VERSION "GM Global B Super Cruise 1 CAN2"
NS_ :

BS_:
BU_: ACP3_MCU CGM ECP_E EBCM EPS ARS BCM DSM TCP VICM RRR_SIDE Vector__XXX

BO_ 47 ECP_E_AXLE_TORQUE: 32 ECP_E
 SG_ AUTHENTICATOR : 7|32@0+ (1,0) [0|4294967295] "" Vector__XXX
 SG_ SECOC_FRESHNESS : 39|5@0+ (1,0) [0|31] "" Vector__XXX
 SG_ SECOC_AUX : 34|3@0+ (1,0) [0|7] "" Vector__XXX
 SG_ ActualAxleTorque : 47|15@0+ (2,-22534) [-22534|43000] "Nm" Vector__XXX
 SG_ ActualAxleTorqueInvalid : 48|1@0+ (1,0) [0|1] "" Vector__XXX
 SG_ SecondaryAxleTorque : 176|15@0+ (2,-22534) [-22534|43000] "Nm" Vector__XXX
 SG_ SecondaryAxleTorqueInvalid : 193|1@0+ (1,0) [0|1] "" Vector__XXX
 SG_ RollingCounter : 239|2@0+ (1,0) [0|3] "" Vector__XXX

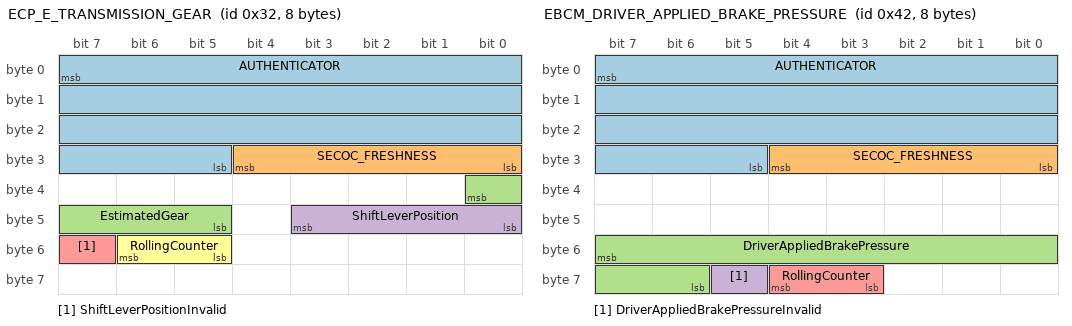
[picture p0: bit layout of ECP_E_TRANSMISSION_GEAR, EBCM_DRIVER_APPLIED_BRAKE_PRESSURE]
BO_ 50 ECP_E_TRANSMISSION_GEAR: 8 ECP_E
 SG_ AUTHENTICATOR : 7|27@0+ (1,0) [0|134217727] "" Vector__XXX
 SG_ SECOC_FRESHNESS : 28|5@0+ (1,0) [0|31] "" Vector__XXX
 SG_ EstimatedGear : 32|4@0+ (1,0) [0|15] "" Vector__XXX
 SG_ ShiftLeverPosition : 43|4@0+ (1,0) [0|15] "" Vector__XXX
 SG_ ShiftLeverPositionInvalid : 55|1@0+ (1,0) [0|1] "" Vector__XXX
 SG_ RollingCounter : 54|2@0+ (1,0) [0|3] "" Vector__XXX

BO_ 58 CAN2_RX_03A: 20 EPS
 SG_ AUTHENTICATOR : 7|32@0+ (1,0) [0|4294967295] "" Vector__XXX
 SG_ SECOC_FRESHNESS : 39|5@0+ (1,0) [0|31] "" Vector__XXX
 SG_ SECOC_AUX : 34|3@0+ (1,0) [0|7] "" Vector__XXX
 SG_ RollingCounter : 135|2@0+ (1,0) [0|3] "" Vector__XXX

BO_ 59 EBCM_BRAKE_WHEEL_DATA: 64 EBCM
 SG_ AUTHENTICATOR : 7|32@0+ (1,0) [0|4294967295] "" Vector__XXX
 SG_ SECOC_FRESHNESS : 39|5@0+ (1,0) [0|31] "" Vector__XXX
 SG_ SECOC_AUX : 34|3@0+ (1,0) [0|7] "" Vector__XXX
 SG_ BrakePedalPosition : 105|8@0+ (0.392157,0) [0|100] "%" Vector__XXX
 SG_ BrakePedalPositionInvalid : 113|1@0+ (1,0) [0|1] "" Vector__XXX
 SG_ ChassisBrakeAxleTorque : 209|14@0+ (2,0) [0|32766] "Nm" Vector__XXX
 SG_ ChassisBrakeAxleTorqueInvalid : 227|1@0+ (1,0) [0|1] "" Vector__XXX
 SG_ DriverIntendedTotalBrakeTorque : 226|14@0+ (2,0) [0|32766] "Nm" Vector__XXX
 SG_ LeftFrontWheelDistanceEdges : 244|11@0+ (1,0) [0|2047] "edges" Vector__XXX
 SG_ LeftFrontWheelDistanceInvalid : 249|1@0+ (1,0) [0|1] "" Vector__XXX
 SG_ RightFrontWheelDistanceEdges : 248|11@0+ (1,0) [0|2047] "edges" Vector__XXX
 SG_ RightFrontWheelDistanceInvalid : 269|1@0+ (1,0) [0|1] "" Vector__XXX
 SG_ FrontWheelDistanceResetOccurrence : 268|1@0+ (1,0) [0|1] "" Vector__XXX
 SG_ LeftRearWheelDistanceEdges : 303|11@0+ (1,0) [0|2047] "edges" Vector__XXX
 SG_ LeftRearWheelDistanceInvalid : 308|1@0+ (1,0) [0|1] "" Vector__XXX
 SG_ RightRearWheelDistanceEdges : 307|11@0+ (1,0) [0|2047] "edges" Vector__XXX
 SG_ RightRearWheelDistanceInvalid : 312|1@0+ (1,0) [0|1] "" Vector__XXX
 SG_ RearWheelDistanceResetOccurrence : 327|1@0+ (1,0) [0|1] "" Vector__XXX
 SG_ LeftFrontWheelAngularVelocity : 356|14@0- (0.004,0) [-32.768|32.764] "rad/s" Vector__XXX
 SG_ LeftFrontWheelAngularVelocityInvalid : 374|1@0+ (1,0) [0|1] "" Vector__XXX
 SG_ RightFrontWheelAngularVelocity : 373|14@0- (0.004,0) [-32.768|32.764] "rad/s" Vector__XXX
 SG_ RightFrontWheelAngularVelocityInvalid : 391|1@0+ (1,0) [0|1] "" Vector__XXX
 SG_ LeftRearWheelAngularVelocity : 390|14@0- (0.004,0) [-32.768|32.764] "rad/s" Vector__XXX
 SG_ LeftRearWheelAngularVelocityInvalid : 392|1@0+ (1,0) [0|1] "" Vector__XXX
 SG_ RightRearWheelAngularVelocity : 407|14@0- (0.004,0) [-32.768|32.764] "rad/s" Vector__XXX
 SG_ RightRearWheelAngularVelocityInvalid : 409|1@0+ (1,0) [0|1] "" Vector__XXX
 SG_ RollingCounter : 455|2@0+ (1,0) [0|3] "" Vector__XXX

BO_ 62 CAN2_RX_03E: 8 BCM

BO_ 63 ECP_E_NOMINAL_ROAD_LOAD_AXLE_TORQUE: 4 ECP_E
 SG_ NominalRoadLoadAxleTorque : 7|19@0- (0.125,-22534) [-55302|10233.875] "Nm" Vector__XXX

BO_ 66 EBCM_DRIVER_APPLIED_BRAKE_PRESSURE: 8 EBCM
 SG_ AUTHENTICATOR : 7|27@0+ (1,0) [0|134217727] "" Vector__XXX
 SG_ SECOC_FRESHNESS : 28|5@0+ (1,0) [0|31] "" Vector__XXX
 SG_ DriverAppliedBrakePressure : 55|10@0+ (20,0) [0|20460] "" Vector__XXX
 SG_ DriverAppliedBrakePressureInvalid : 61|1@0+ (1,0) [0|1] "" Vector__XXX
 SG_ RollingCounter : 60|2@0+ (1,0) [0|3] "" Vector__XXX

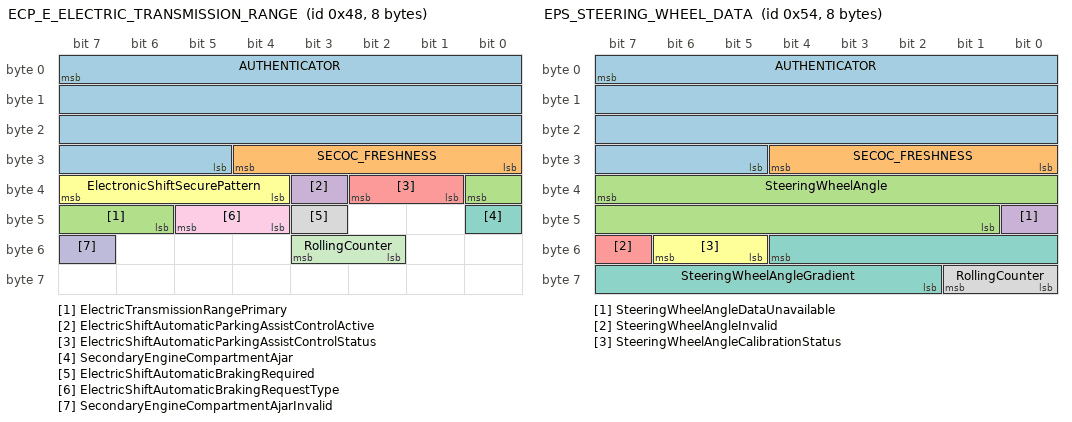
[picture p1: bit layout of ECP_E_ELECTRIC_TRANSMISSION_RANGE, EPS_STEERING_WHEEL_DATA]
BO_ 72 ECP_E_ELECTRIC_TRANSMISSION_RANGE: 8 ECP_E
 SG_ AUTHENTICATOR : 7|27@0+ (1,0) [0|134217727] "" Vector__XXX
 SG_ SECOC_FRESHNESS : 28|5@0+ (1,0) [0|31] "" Vector__XXX
 SG_ ElectricTransmissionRangePrimary : 32|3@0+ (1,0) [0|7] "" Vector__XXX
 SG_ ElectricShiftAutomaticParkingAssistControlActive : 35|1@0+ (1,0) [0|1] "" Vector__XXX
 SG_ ElectricShiftAutomaticParkingAssistControlStatus : 34|2@0+ (1,0) [0|3] "" Vector__XXX
 SG_ ElectronicShiftSecurePattern : 39|4@0+ (1,0) [0|15] "" Vector__XXX
 SG_ SecondaryEngineCompartmentAjar : 40|1@0+ (1,0) [0|1] "" Vector__XXX
 SG_ ElectricShiftAutomaticBrakingRequired : 43|1@0+ (1,0) [0|1] "" Vector__XXX
 SG_ ElectricShiftAutomaticBrakingRequestType : 45|2@0+ (1,0) [0|3] "" Vector__XXX
 SG_ SecondaryEngineCompartmentAjarInvalid : 55|1@0+ (1,0) [0|1] "" Vector__XXX
 SG_ RollingCounter : 51|2@0+ (1,0) [0|3] "" Vector__XXX

BO_ 84 EPS_STEERING_WHEEL_DATA: 8 EPS
 SG_ AUTHENTICATOR : 7|27@0+ (1,0) [0|134217727] "" Vector__XXX
 SG_ SECOC_FRESHNESS : 28|5@0+ (1,0) [0|31] "" Vector__XXX
 SG_ SteeringWheelAngle : 39|15@0- (0.0625,0) [-1024|1023.9375] "deg" Vector__XXX
 SG_ SteeringWheelAngleDataUnavailable : 40|1@0+ (1,0) [0|1] "" Vector__XXX
 SG_ SteeringWheelAngleInvalid : 55|1@0+ (1,0) [0|1] "" Vector__XXX
 SG_ SteeringWheelAngleCalibrationStatus : 54|2@0+ (1,0) [0|3] "" Vector__XXX
 SG_ SteeringWheelAngleGradient : 52|11@0- (2,0) [-2048|2046] "deg/s" Vector__XXX
 SG_ RollingCounter : 57|2@0+ (1,0) [0|3] "" Vector__XXX

BO_ 87 ACP3_MCU_HOST_VEHICLE_DYNAMICS: 32 ACP3_MCU
 SG_ AUTHENTICATOR : 7|32@0+ (1,0) [0|4294967295] "" Vector__XXX
 SG_ SECOC_FRESHNESS : 39|5@0+ (1,0) [0|31] "" Vector__XXX
 SG_ SECOC_AUX : 34|3@0+ (1,0) [0|7] "" Vector__XXX
 SG_ VehicleLateralVelocity : 46|8@0+ (0.05,-6.4) [-6.4|6.35] "m/s" Vector__XXX
 SG_ DynField02 : 47|1@0+ (1,0) [0|1] "" Vector__XXX
 SG_ VehicleLongitudinalVelocity : 53|12@0+ (0.0625,-128) [-128|127.9375] "m/s" Vector__XXX
 SG_ DynField04 : 54|1@0+ (1,0) [0|1] "" Vector__XXX
 SG_ DynField05 : 56|16@0- (0.00001,0) [-0.32768|0.32767] "1/m" Vector__XXX
 SG_ DynField06 : 57|1@0+ (1,0) [0|1] "" Vector__XXX
 SG_ DynField07 : 72|15@0+ (0.001,-16) [-16|16.767] "1/(m*s)" Vector__XXX
 SG_ DynField08 : 89|2@0+ (1,0) [0|3] "" Vector__XXX
 SG_ VehicleSideslipAngle : 103|12@0+ (0.0625,-128) [-128|127.9375] "deg" Vector__XXX
 SG_ DynField10 : 107|14@0+ (1,-8192) [-8192|8191] "m" Vector__XXX
 SG_ DynField11 : 125|8@0+ (0.1,-12.8) [-12.8|12.7] "m" Vector__XXX
 SG_ DynField12 : 131|12@0+ (0.0625,-128) [-128|127.9375] "m/s" Vector__XXX
 SG_ DynField13 : 133|2@0+ (1,0) [0|3] "" Vector__XXX
 SG_ VehicleYawRate : 150|12@0+ (0.0625,-128) [-128|127.9375] "deg/s" Vector__XXX
 SG_ DynField15 : 151|1@0+ (1,0) [0|1] "" Vector__XXX
 SG_ DynField16 : 153|2@0+ (1,0) [0|3] "" Vector__XXX
 SG_ DynField17 : 154|1@0+ (1,0) [0|1] "" Vector__XXX
 SG_ SourceTime : 167|32@0+ (1,0) [0|4294967295] "ms" Vector__XXX
 SG_ RollingCounter : 193|2@0+ (1,0) [0|3] "" Vector__XXX
 SG_ DynField20 : 195|2@0+ (1,0) [0|3] "" Vector__XXX
 SG_ DynField21 : 199|2@0+ (1,0) [0|3] "" Vector__XXX
 SG_ DynField22 : 201|9@0- (1,0) [-256|255] "mm" Vector__XXX
 SG_ DynField23 : 203|2@0+ (1,0) [0|3] "" Vector__XXX
 SG_ DynField24 : 207|4@0+ (1,0) [0|15] "" Vector__XXX
 SG_ DynField25 : 208|1@0+ (1,0) [0|1] "" Vector__XXX
 SG_ DynField26 : 223|1@0+ (1,0) [0|1] "" Vector__XXX
 SG_ FrontRoadWheelAngle : 222|10@0- (0.00436332313,0) [-2.23402144256|2.22965811943] "rad" Vector__XXX
 SG_ FrontRoadWheelAngleStatus : 228|1@0+ (1,0) [0|1] "" Vector__XXX
 SG_ DynField27 : 227|2@0+ (1,0) [0|3] "" Vector__XXX

BO_ 174 CAN2_RX_0AE: 6 ECP_E

BO_ 175 CAN2_RX_0AF: 6 ECP_E

BO_ 182 CAN2_RX_0B6: 4 CGM

BO_ 186 CAN2_RX_0BA: 12 CGM

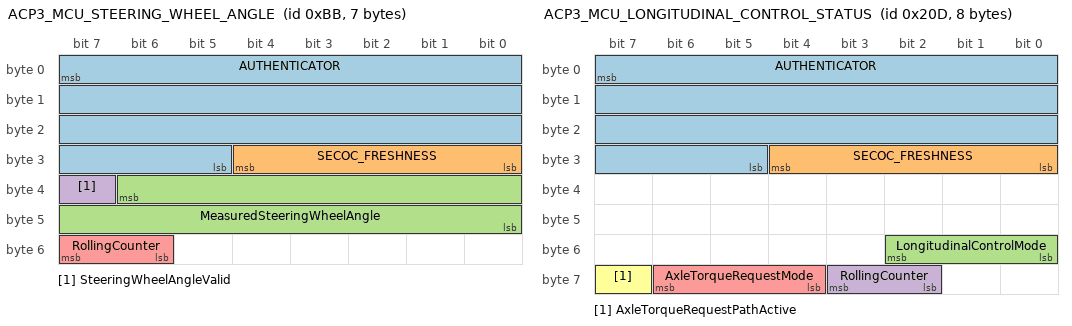
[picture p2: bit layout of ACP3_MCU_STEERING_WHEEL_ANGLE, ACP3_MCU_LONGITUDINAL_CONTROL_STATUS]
BO_ 187 ACP3_MCU_STEERING_WHEEL_ANGLE: 7 ACP3_MCU
 SG_ AUTHENTICATOR : 7|27@0+ (1,0) [0|134217727] "" Vector__XXX
 SG_ SECOC_FRESHNESS : 28|5@0+ (1,0) [0|31] "" Vector__XXX
 SG_ MeasuredSteeringWheelAngle : 38|15@0- (0.0625,0) [-1024|1023.9375] "deg" Vector__XXX
 SG_ SteeringWheelAngleValid : 39|1@0+ (1,0) [0|1] "" Vector__XXX
 SG_ RollingCounter : 55|2@0+ (1,0) [0|3] "" Vector__XXX

BO_ 192 CAN2_RX_0C0: 2 EBCM

BO_ 225 ACP3_MCU_0E1: 16 ACP3_MCU

BO_ 226 CAN2_RX_0E2: 20 ECP_E
 SG_ AUTHENTICATOR : 7|32@0+ (1,0) [0|4294967295] "" Vector__XXX
 SG_ SECOC_FRESHNESS : 39|5@0+ (1,0) [0|31] "" Vector__XXX
 SG_ SECOC_AUX : 34|3@0+ (1,0) [0|7] "" Vector__XXX

BO_ 525 ACP3_MCU_LONGITUDINAL_CONTROL_STATUS: 8 ACP3_MCU
 SG_ AUTHENTICATOR : 7|27@0+ (1,0) [0|134217727] "" Vector__XXX
 SG_ SECOC_FRESHNESS : 28|5@0+ (1,0) [0|31] "" Vector__XXX
 SG_ LongitudinalControlMode : 48|3@1+ (1,0) [0|7] "" Vector__XXX
 SG_ RollingCounter : 58|2@1+ (1,0) [0|3] "" Vector__XXX
 SG_ AxleTorqueRequestMode : 60|3@1+ (1,0) [0|7] "" Vector__XXX
 SG_ AxleTorqueRequestPathActive : 63|1@1+ (1,0) [0|1] "" Vector__XXX

BO_ 526 ACP3_MCU_LONGITUDINAL_REQUEST_STATUS: 16 ACP3_MCU
 SG_ AUTHENTICATOR : 7|32@0+ (1,0) [0|4294967295] "" Vector__XXX
 SG_ SECOC_FRESHNESS : 39|5@0+ (1,0) [0|31] "" Vector__XXX
 SG_ SECOC_AUX : 34|3@0+ (1,0) [0|7] "" Vector__XXX
 SG_ AxleTorqueRequestActive : 47|1@0+ (1,0) [0|1] "" Vector__XXX
 SG_ AdaptiveCruiseBrakeControlActive : 71|1@0+ (1,0) [0|1] "" Vector__XXX
 SG_ AdaptiveCruiseBrakeRequestActive : 70|1@0+ (1,0) [0|1] "" Vector__XXX
 SG_ CollisionMitigationBrakeTorqueRequestActive : 86|1@0+ (1,0) [0|1] "" Vector__XXX
 SG_ LaneCenteringAcceleratorLimitRequest : 101|1@0+ (1,0) [0|1] "" Vector__XXX

BO_ 545 CAN2_RX_221: 48 Vector__XXX

BO_ 586 CAN2_RX_24A: 8 Vector__XXX

BO_ 587 ACP3_MCU_AXLE_TORQUE_STATUS: 12 ACP3_MCU
 SG_ AUTHENTICATOR : 7|32@0+ (1,0) [0|4294967295] "" Vector__XXX
 SG_ SECOC_FRESHNESS : 39|5@0+ (1,0) [0|31] "" Vector__XXX
 SG_ SECOC_AUX : 34|3@0+ (1,0) [0|7] "" Vector__XXX
 SG_ AxleTorqueFieldA : 47|15@0+ (2.0,-22534) [-22534|43000] "" Vector__XXX
 SG_ AxleTorqueFieldB : 48|14@0+ (2.0,-22534) [-22534|10232] "" Vector__XXX
 SG_ AxleTorqueStatusA : 66|2@0+ (1,0) [0|3] "" Vector__XXX
 SG_ AxleTorqueStatusB : 64|2@0+ (1,0) [0|3] "" Vector__XXX
 SG_ AxleTorqueValid : 78|1@0+ (1,0) [0|1] "" Vector__XXX
 SG_ RollingCounter : 89|2@0+ (1,0) [0|3] "" Vector__XXX

BO_ 597 CAN2_RX_255: 8 CGM

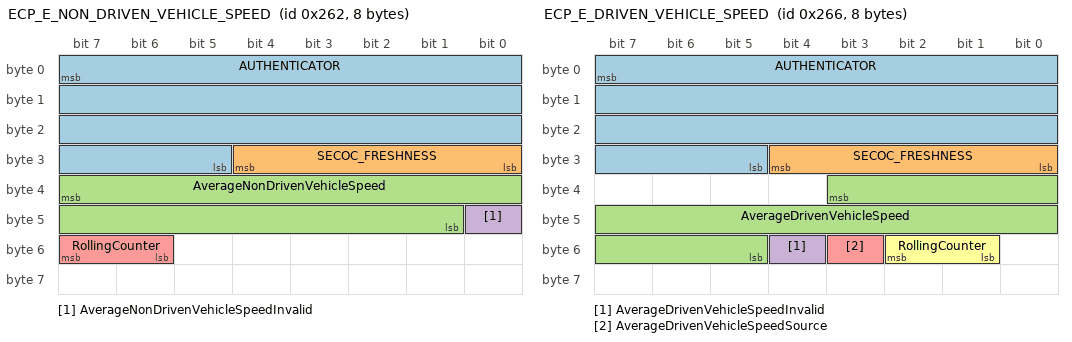
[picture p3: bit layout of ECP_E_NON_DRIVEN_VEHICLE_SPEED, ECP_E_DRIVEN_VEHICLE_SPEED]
BO_ 610 ECP_E_NON_DRIVEN_VEHICLE_SPEED: 8 ECP_E
 SG_ AUTHENTICATOR : 7|27@0+ (1,0) [0|134217727] "" Vector__XXX
 SG_ SECOC_FRESHNESS : 28|5@0+ (1,0) [0|31] "" Vector__XXX
 SG_ AverageNonDrivenVehicleSpeed : 39|15@0+ (0.015625,0) [0|511.984375] "m/s" Vector__XXX
 SG_ AverageNonDrivenVehicleSpeedInvalid : 40|1@0+ (1,0) [0|1] "" Vector__XXX
 SG_ RollingCounter : 55|2@0+ (1,0) [0|3] "" Vector__XXX

BO_ 614 ECP_E_DRIVEN_VEHICLE_SPEED: 8 ECP_E
 SG_ AUTHENTICATOR : 7|27@0+ (1,0) [0|134217727] "" Vector__XXX
 SG_ SECOC_FRESHNESS : 28|5@0+ (1,0) [0|31] "" Vector__XXX
 SG_ AverageDrivenVehicleSpeed : 35|15@0+ (0.015625,0) [0|511.984375] "m/s" Vector__XXX
 SG_ AverageDrivenVehicleSpeedInvalid : 52|1@0+ (1,0) [0|1] "" Vector__XXX
 SG_ AverageDrivenVehicleSpeedSource : 51|1@0+ (1,0) [0|1] "" Vector__XXX
 SG_ RollingCounter : 50|2@0+ (1,0) [0|3] "" Vector__XXX

BO_ 615 CAN2_RX_267: 20 ECP_E
 SG_ AUTHENTICATOR : 7|32@0+ (1,0) [0|4294967295] "" Vector__XXX
 SG_ SECOC_FRESHNESS : 39|5@0+ (1,0) [0|31] "" Vector__XXX
 SG_ SECOC_AUX : 34|3@0+ (1,0) [0|7] "" Vector__XXX

BO_ 616 CAN2_RX_268: 8 VICM

BO_ 622 CAN2_RX_26E: 8 CGM

BO_ 624 EBCM_WHEEL_ROTATION_DIRECTIONAL_STATUS: 12 EBCM
 SG_ AUTHENTICATOR : 7|32@0+ (1,0) [0|4294967295] "" Vector__XXX
 SG_ SECOC_FRESHNESS : 39|5@0+ (1,0) [0|31] "" Vector__XXX
 SG_ SECOC_AUX : 34|3@0+ (1,0) [0|7] "" Vector__XXX
 SG_ ActualVehicleAcceleration : 43|12@0- (0.01,0) [-20.48|20.47] "m/s^2" Vector__XXX
 SG_ ActualVehicleAccelerationInvalid : 63|1@0+ (1,0) [0|1] "" Vector__XXX
 SG_ LeftFrontWheelDirection : 62|3@0+ (1,0) [0|7] "" Vector__XXX
 SG_ LeftRearWheelDirection : 59|3@0+ (1,0) [0|7] "" Vector__XXX
 SG_ RightFrontWheelDirection : 56|3@0+ (1,0) [0|7] "" Vector__XXX
 SG_ RightRearWheelDirection : 69|3@0+ (1,0) [0|7] "" Vector__XXX
 SG_ RollingCounter : 66|2@0+ (1,0) [0|3] "" Vector__XXX

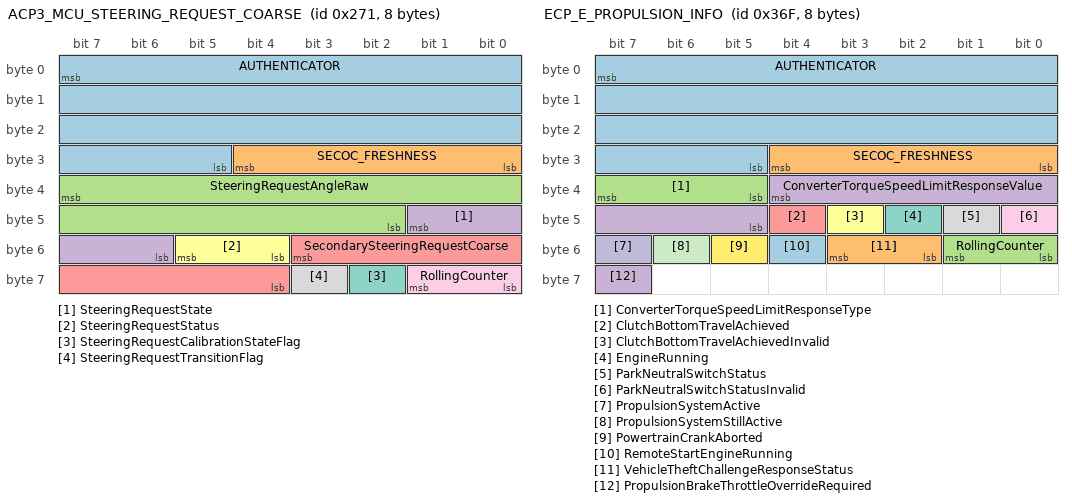
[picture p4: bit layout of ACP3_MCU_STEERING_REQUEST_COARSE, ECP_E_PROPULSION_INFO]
BO_ 625 ACP3_MCU_STEERING_REQUEST_COARSE: 8 ACP3_MCU
 SG_ AUTHENTICATOR : 7|27@0+ (1,0) [0|134217727] "" Vector__XXX
 SG_ SECOC_FRESHNESS : 28|5@0+ (1,0) [0|31] "" Vector__XXX
 SG_ SteeringRequestAngleRaw : 39|14@0- (0.1,0) [-819.2|819.1] "" Vector__XXX
 SG_ SteeringRequestState : 41|4@0+ (1,0) [0|15] "" Vector__XXX
 SG_ SecondarySteeringRequestCoarse : 51|8@0- (0.1,0) [-12.8|12.7] "Nm" Vector__XXX
 SG_ SteeringRequestStatus : 53|2@0+ (1,0) [0|3] "" Vector__XXX
 SG_ SteeringRequestCalibrationStateFlag : 58|1@0+ (1,0) [0|1] "" Vector__XXX
 SG_ SteeringRequestTransitionFlag : 59|1@0+ (1,0) [0|1] "" Vector__XXX
 SG_ RollingCounter : 57|2@0+ (1,0) [0|3] "" Vector__XXX

BO_ 634 CAN2_RX_27A: 8 BCM

BO_ 635 CAN2_RX_AUTHENTICATED_27B: 8 EBCM
 SG_ AUTHENTICATOR : 7|27@0+ (1,0) [0|134217727] "" ACP3_MCU
 SG_ SECOC_FRESHNESS : 28|5@0+ (1,0) [0|31] "" ACP3_MCU

BO_ 640 CAN2_RX_280: 8 CGM

BO_ 644 ACP3_MCU_STEERING_REQUEST_HIGH_RES: 12 ACP3_MCU
 SG_ AUTHENTICATOR : 7|32@0+ (1,0) [0|4294967295] "" Vector__XXX
 SG_ SECOC_FRESHNESS : 39|5@0+ (1,0) [0|31] "" Vector__XXX
 SG_ SECOC_AUX : 34|3@0+ (1,0) [0|7] "" Vector__XXX
 SG_ SteeringRequestAngleRaw : 47|14@0- (0.1,0) [-819.2|819.1] "" Vector__XXX
 SG_ SecondarySteeringRequestHighResolution : 49|11@0- (0.01,0) [-10.24|10.23] "Nm" Vector__XXX
 SG_ SteeringRequestCalibrationStateFlag : 64|1@0+ (1,0) [0|1] "" Vector__XXX
 SG_ SteeringRequestStatus : 66|2@0+ (1,0) [0|3] "" Vector__XXX
 SG_ SteeringRequestState : 70|4@0+ (1,0) [0|15] "" Vector__XXX
 SG_ SteeringRequestTransitionFlag : 79|1@0+ (1,0) [0|1] "" Vector__XXX
 SG_ RollingCounter : 89|2@0+ (1,0) [0|3] "" Vector__XXX

BO_ 659 CAN2_RX_293: 12 CGM

BO_ 674 CAN2_RX_2A2: 8 Vector__XXX
 SG_ SECOC_FRESHNESS_VALUE : 0|32@1+ (1,0) [0|4294967295] "" Vector__XXX

BO_ 675 EPS_STEERING_WHEEL_DATA_FV: 8 EPS
 SG_ SECOC_FRESHNESS_VALUE : 0|32@1+ (1,0) [0|4294967295] "" Vector__XXX

BO_ 683 CAN2_RX_2AB: 8 Vector__XXX

BO_ 691 EBCM_BRAKE_DATA_FV: 8 EBCM
 SG_ SECOC_FRESHNESS_VALUE : 0|32@1+ (1,0) [0|4294967295] "" Vector__XXX

BO_ 693 CAN2_RX_2B5: 8 Vector__XXX

BO_ 694 CAN2_RX_AUTHENTICATION_2B6: 8 Vector__XXX
 SG_ SECOC_FRESHNESS_VALUE : 0|32@1+ (1,0) [0|4294967295] "" ACP3_MCU

BO_ 701 ACP3_MCU_2BD: 2 ACP3_MCU

BO_ 702 CAN2_RX_2BE: 4 CGM

BO_ 703 CAN2_RX_2BF: 2 EBCM

BO_ 725 CAN2_RX_2D5: 12 CGM

BO_ 726 CAN2_RX_2D6: 5 CGM

BO_ 727 CAN2_RX_2D7: 8 TCP

BO_ 728 CAN2_RX_2D8: 8 CGM

BO_ 873 CAN2_RX_369: 8 EBCM
 SG_ AUTHENTICATOR : 7|27@0+ (1,0) [0|134217727] "" Vector__XXX
 SG_ SECOC_FRESHNESS : 28|5@0+ (1,0) [0|31] "" Vector__XXX

BO_ 876 CAN2_RX_36C: 16 CGM

BO_ 878 CAN2_RX_36E: 8 BCM

BO_ 879 ECP_E_PROPULSION_INFO: 8 ECP_E
 SG_ AUTHENTICATOR : 7|27@0+ (1,0) [0|134217727] "" Vector__XXX
 SG_ SECOC_FRESHNESS : 28|5@0+ (1,0) [0|31] "" Vector__XXX
 SG_ ConverterTorqueSpeedLimitResponseType : 39|3@0+ (1,0) [0|7] "" Vector__XXX
 SG_ ConverterTorqueSpeedLimitResponseValue : 36|8@0+ (1,0) [0|255] "" Vector__XXX
 SG_ ClutchBottomTravelAchieved : 44|1@0+ (1,0) [0|1] "" Vector__XXX
 SG_ ClutchBottomTravelAchievedInvalid : 43|1@0+ (1,0) [0|1] "" Vector__XXX
 SG_ EngineRunning : 42|1@0+ (1,0) [0|1] "" Vector__XXX
 SG_ ParkNeutralSwitchStatus : 41|1@0+ (1,0) [0|1] "" Vector__XXX
 SG_ ParkNeutralSwitchStatusInvalid : 40|1@0+ (1,0) [0|1] "" Vector__XXX
 SG_ PropulsionSystemActive : 55|1@0+ (1,0) [0|1] "" Vector__XXX
 SG_ PropulsionSystemStillActive : 54|1@0+ (1,0) [0|1] "" Vector__XXX
 SG_ PowertrainCrankAborted : 53|1@0+ (1,0) [0|1] "" Vector__XXX
 SG_ RemoteStartEngineRunning : 52|1@0+ (1,0) [0|1] "" Vector__XXX
 SG_ VehicleTheftChallengeResponseStatus : 51|2@0+ (1,0) [0|3] "" Vector__XXX
 SG_ RollingCounter : 49|2@0+ (1,0) [0|3] "" Vector__XXX
 SG_ PropulsionBrakeThrottleOverrideRequired : 63|1@0+ (1,0) [0|1] "" Vector__XXX

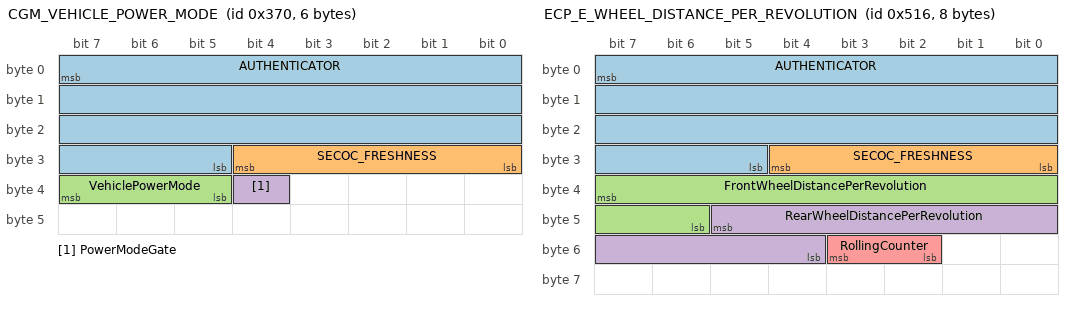
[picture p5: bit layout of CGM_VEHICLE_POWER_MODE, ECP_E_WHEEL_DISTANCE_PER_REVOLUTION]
BO_ 880 CGM_VEHICLE_POWER_MODE: 6 CGM
 SG_ AUTHENTICATOR : 7|27@0+ (1,0) [0|134217727] "" Vector__XXX
 SG_ SECOC_FRESHNESS : 28|5@0+ (1,0) [0|31] "" Vector__XXX
 SG_ VehiclePowerMode : 37|3@1+ (1,0) [0|7] "" Vector__XXX
 SG_ PowerModeGate : 36|1@1+ (1,0) [0|1] "" Vector__XXX

BO_ 898 CAN2_RX_382: 8 CGM

BO_ 901 CAN2_RX_385: 8 Vector__XXX

BO_ 902 ACP3_MCU_LONGITUDINAL_REQUEST_STATUS_FV: 8 ACP3_MCU
 SG_ SECOC_FRESHNESS_VALUE : 0|32@1+ (1,0) [0|4294967295] "" Vector__XXX

BO_ 904 CAN2_RX_388: 8 Vector__XXX

BO_ 905 CAN2_RX_389: 8 Vector__XXX
 SG_ SECOC_FRESHNESS_VALUE : 0|32@1+ (1,0) [0|4294967295] "" Vector__XXX

BO_ 906 CAN2_RX_38A: 8 Vector__XXX
 SG_ SECOC_FRESHNESS_VALUE : 0|32@1+ (1,0) [0|4294967295] "" Vector__XXX

BO_ 907 CAN2_RX_38B: 8 Vector__XXX

BO_ 909 CAN2_RX_38D: 8 Vector__XXX

BO_ 914 ACP3_MCU_HOST_VEHICLE_DYNAMICS_FV: 8 ACP3_MCU
 SG_ SECOC_FRESHNESS_VALUE : 0|32@1+ (1,0) [0|4294967295] "" Vector__XXX

BO_ 919 EBCM_WHEEL_ROTATION_DIRECTIONAL_STATUS_FV: 8 EBCM
 SG_ SECOC_FRESHNESS_VALUE : 0|32@1+ (1,0) [0|4294967295] "" Vector__XXX

BO_ 920 CAN2_RX_398: 8 Vector__XXX

BO_ 923 CAN2_RX_39B: 8 Vector__XXX

BO_ 924 ACP3_MCU_STEERING_REQUEST_COARSE_FV: 8 ACP3_MCU
 SG_ SECOC_FRESHNESS_VALUE : 0|32@1+ (1,0) [0|4294967295] "" Vector__XXX

BO_ 925 ACP3_MCU_LONGITUDINAL_CONTROL_STATUS_FV: 8 ACP3_MCU
 SG_ SECOC_FRESHNESS_VALUE : 0|32@1+ (1,0) [0|4294967295] "" Vector__XXX

BO_ 927 ACP3_MCU_STEERING_WHEEL_ANGLE_FV: 8 ACP3_MCU
 SG_ SECOC_FRESHNESS_VALUE : 0|32@1+ (1,0) [0|4294967295] "" Vector__XXX

BO_ 930 CAN2_RX_3A2: 8 CGM

BO_ 934 CAN2_RX_3A6: 6 ECP_E

BO_ 938 CAN2_RX_3AA: 6 EBCM

BO_ 941 ACP3_MCU_3AD: 6 ACP3_MCU

BO_ 945 CAN2_RX_3B1: 6 Vector__XXX

BO_ 947 ACP3_MCU_3B3: 6 ACP3_MCU

BO_ 949 ACP3_MCU_3B5: 8 ACP3_MCU

BO_ 950 ACP3_MCU_3B6: 8 ACP3_MCU

BO_ 951 ACP3_MCU_3B7: 8 ACP3_MCU

BO_ 952 ACP3_MCU_3B8: 8 ACP3_MCU

BO_ 962 CAN2_RX_CGM_SYSTEM_POWER_MODE_STATUS: 8 CGM
 SG_ SystemPowerModeProtectionFailSafe : 0|1@1+ (1,0) [0|1] "" Vector__XXX

BO_ 963 CAN2_RX_CGM_AUTHENTICATED_POWER_MODE: 8 CGM
 SG_ SystemPowerModeActive : 40|1@1+ (1,0) [0|1] "" Vector__XXX
 SG_ PrimaryRunCrankCommand : 44|4@1+ (1,0) [0|15] "" Vector__XXX

BO_ 964 CAN2_RX_3C4: 8 CGM

BO_ 971 ACP3_MCU_AXLE_TORQUE_STATUS_FV: 8 ACP3_MCU
 SG_ SECOC_FRESHNESS_VALUE : 0|32@1+ (1,0) [0|4294967295] "" Vector__XXX

BO_ 972 CAN2_RX_3CC: 8 Vector__XXX

BO_ 974 ACP3_MCU_STEERING_REQUEST_HIGH_RES_FV: 8 ACP3_MCU
 SG_ SECOC_FRESHNESS_VALUE : 0|32@1+ (1,0) [0|4294967295] "" Vector__XXX

BO_ 1026 ACP3_MCU_402: 24 ACP3_MCU

BO_ 1027 ACP3_MCU_403: 6 ACP3_MCU

BO_ 1117 ACP3_MCU_UNKNOWN_45D: 8 ACP3_MCU
 SG_ AUTHENTICATOR : 7|27@0+ (1,0) [0|134217727] "" Vector__XXX
 SG_ SECOC_FRESHNESS : 28|5@0+ (1,0) [0|31] "" Vector__XXX

BO_ 1149 CAN2_RX_47D: 8 CGM

BO_ 1152 CAN2_RX_480: 8 CGM

BO_ 1237 ACP3_MCU_4D5: 8 ACP3_MCU

BO_ 1239 ACP3_MCU_4D7: 12 ACP3_MCU

BO_ 1244 CAN2_RX_4DC: 6 CGM

BO_ 1254 ACP3_MCU_4E6: 12 ACP3_MCU

BO_ 1264 CAN2_RX_4F0: 6 ECP_E

BO_ 1285 CAN2_RX_505: 6 Vector__XXX

BO_ 1298 CAN2_RX_512: 8 BCM

BO_ 1302 ECP_E_WHEEL_DISTANCE_PER_REVOLUTION: 8 ECP_E
 SG_ AUTHENTICATOR : 7|27@0+ (1,0) [0|134217727] "" Vector__XXX
 SG_ SECOC_FRESHNESS : 28|5@0+ (1,0) [0|31] "" Vector__XXX
 SG_ FrontWheelDistancePerRevolution : 39|10@0+ (3,800) [800|3869] "mm" Vector__XXX
 SG_ RearWheelDistancePerRevolution : 45|10@0+ (3,800) [800|3869] "mm" Vector__XXX
 SG_ RollingCounter : 51|2@0+ (1,0) [0|3] "" Vector__XXX

BO_ 1304 ACP3_MCU_518: 12 ACP3_MCU

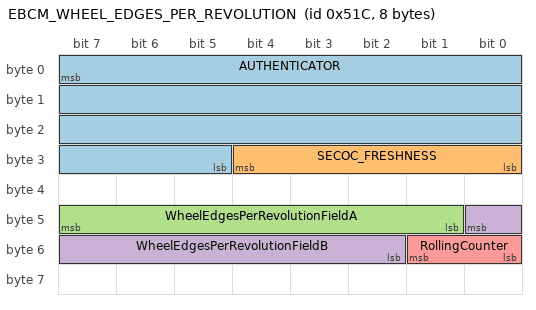
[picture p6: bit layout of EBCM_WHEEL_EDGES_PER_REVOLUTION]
BO_ 1308 EBCM_WHEEL_EDGES_PER_REVOLUTION: 8 EBCM
 SG_ AUTHENTICATOR : 7|27@0+ (1,0) [0|134217727] "" Vector__XXX
 SG_ SECOC_FRESHNESS : 28|5@0+ (1,0) [0|31] "" Vector__XXX
 SG_ WheelEdgesPerRevolutionFieldA : 47|7@0+ (1,30) [30|157] "edges/rev" Vector__XXX
 SG_ WheelEdgesPerRevolutionFieldB : 40|7@0+ (1,30) [30|157] "edges/rev" Vector__XXX
 SG_ RollingCounter : 49|2@0+ (1,0) [0|3] "" Vector__XXX

BO_ 1313 CAN2_RX_521: 8 VICM

BO_ 1314 CAN2_RX_522: 6 DSM

BO_ 1315 CAN2_RX_523: 8 CGM

BO_ 1316 CAN2_RX_524: 8 BCM

BO_ 1318 ACP3_MCU_526: 12 ACP3_MCU

BO_ 1319 CAN2_RX_527: 7 TCP

BO_ 1321 ACP3_MCU_529: 12 ACP3_MCU

BO_ 1323 ACP3_MCU_UNKNOWN_52B: 8 ACP3_MCU
 SG_ AUTHENTICATOR : 7|27@0+ (1,0) [0|134217727] "" Vector__XXX
 SG_ SECOC_FRESHNESS : 28|5@0+ (1,0) [0|31] "" Vector__XXX

BO_ 1324 CAN2_RX_52C: 8 BCM

BO_ 1325 ACP3_MCU_UNKNOWN_52D: 8 ACP3_MCU
 SG_ AUTHENTICATOR : 7|27@0+ (1,0) [0|134217727] "" Vector__XXX
 SG_ SECOC_FRESHNESS : 28|5@0+ (1,0) [0|31] "" Vector__XXX

BO_ 1349 ACP3_MCU_545: 8 ACP3_MCU

BO_ 1354 ACP3_MCU_54A: 8 ACP3_MCU

BO_ 1355 ACP3_MCU_54B: 8 ACP3_MCU

BO_ 1359 CAN2_RX_54F: 8 Vector__XXX

BO_ 1369 ECP_E_VEHICLE_SPEED_FV: 8 ECP_E
 SG_ SECOC_FRESHNESS_VALUE : 0|32@1+ (1,0) [0|4294967295] "" Vector__XXX

BO_ 1373 CAN2_RX_55D: 8 CGM

BO_ 1374 CAN2_RX_55E: 8 Vector__XXX

BO_ 1376 CAN2_RX_560: 8 Vector__XXX
 SG_ SECOC_FRESHNESS_VALUE : 0|32@1+ (1,0) [0|4294967295] "" Vector__XXX

BO_ 1377 CAN2_RX_561: 8 Vector__XXX
 SG_ SECOC_FRESHNESS_VALUE : 0|32@1+ (1,0) [0|4294967295] "" Vector__XXX

BO_ 1383 ACP3_MCU_UNKNOWN_52B_FV: 8 ACP3_MCU
 SG_ SECOC_FRESHNESS_VALUE : 0|32@1+ (1,0) [0|4294967295] "" Vector__XXX

BO_ 1384 CAN2_RX_568: 8 CGM

BO_ 1385 CAN2_RX_569: 8 CGM

BO_ 1387 CAN2_RX_56B: 8 Vector__XXX

BO_ 1393 ACP3_MCU_UNKNOWN_52D_FV: 8 ACP3_MCU
 SG_ SECOC_FRESHNESS_VALUE : 0|32@1+ (1,0) [0|4294967295] "" Vector__XXX

BO_ 1394 CAN2_RX_572: 8 Vector__XXX

BO_ 1396 CAN2_RX_574: 8 Vector__XXX

BO_ 1402 CAN2_RX_57A: 8 Vector__XXX

BO_ 1403 CAN2_RX_57B: 8 Vector__XXX

BO_ 1404 ECP_E_PROPULSION_INFO_FV: 8 ECP_E
 SG_ SECOC_FRESHNESS_VALUE : 0|32@1+ (1,0) [0|4294967295] "" Vector__XXX

BO_ 1405 CGM_VEHICLE_POWER_MODE_FV: 8 CGM
 SG_ SECOC_FRESHNESS_VALUE : 0|32@1+ (1,0) [0|4294967295] "" Vector__XXX

BO_ 1406 ACP3_MCU_57E: 6 ACP3_MCU

BO_ 1407 CAN2_RX_57F: 16 CGM

BO_ 1408 CAN2_RX_580: 6 BCM

BO_ 1409 CAN2_RX_581: 6 BCM

BO_ 1410 CAN2_RX_582: 6 Vector__XXX

BO_ 1412 CAN2_RX_584: 6 RRR_SIDE

BO_ 1415 ACP3_MCU_587: 8 ACP3_MCU

BO_ 1416 ACP3_MCU_588: 12 ACP3_MCU

BO_ 1417 ACP3_MCU_589: 8 ACP3_MCU

BO_ 1421 ACP3_MCU_58D: 6 ACP3_MCU

BO_ 1422 ACP3_MCU_58E: 8 ACP3_MCU

BO_ 1424 CAN2_RX_590: 8 CGM

BO_ 1426 CAN2_RX_592: 8 Vector__XXX

BO_ 1427 CAN2_RX_593: 6 Vector__XXX

BO_ 1428 CAN2_RX_594: 6 Vector__XXX

BO_ 1429 CAN2_RX_595: 6 Vector__XXX

BO_ 1430 CAN2_RX_596: 6 Vector__XXX

BO_ 1431 ACP3_MCU_597: 6 ACP3_MCU

BO_ 1433 CAN2_RX_599: 6 Vector__XXX

BO_ 1435 CAN2_RX_59B: 6 Vector__XXX

BO_ 1441 CAN2_RX_5A1: 32 CGM

BO_ 1442 CAN2_RX_5A2: 32 CGM

BO_ 1444 CAN2_RX_5A4: 6 CGM

BO_ 1449 ACP3_MCU_5A9: 6 ACP3_MCU

BO_ 1466 CAN2_RX_5BA: 8 CGM

BO_ 1469 CAN2_RX_5BD: 6 CGM

BO_ 1476 CAN2_RX_5C4: 6 CGM

BO_ 1481 CAN2_RX_5C9: 8 EBCM

BO_ 1482 CAN2_RX_5CA: 6 EBCM

BO_ 1483 CAN2_RX_5CB: 8 EBCM

BO_ 1490 CAN2_RX_5D2: 6 Vector__XXX

BO_ 1498 ACP3_MCU_5DA: 6 ACP3_MCU

BO_ 1499 ACP3_MCU_5DB: 6 ACP3_MCU

BO_ 1500 ACP3_MCU_5DC: 8 ACP3_MCU

BO_ 1529 CAN2_RX_5F9: 32 CGM

BO_ 1535 ACP3_MCU_5FF: 6 ACP3_MCU

BO_ 1811 ACP3_MCU_713: 6 ACP3_MCU

BO_ 1818 ACP3_MCU_71A: 6 ACP3_MCU

BO_ 1822 ACP3_MCU_71E: 6 ACP3_MCU

BO_ 1828 ACP3_MCU_724: 8 ACP3_MCU

BO_ 1829 ACP3_MCU_725: 8 ACP3_MCU

BO_ 1949 ACP3_MCU_UNKNOWN_45D_FV: 8 ACP3_MCU
 SG_ SECOC_FRESHNESS_VALUE : 0|32@1+ (1,0) [0|4294967295] "" Vector__XXX

BO_ 2147745830 ACP3_MCU_NodeStatus_CAN2: 1 ACP3_MCU
 SG_ NodeStatusBit0 : 0|1@1+ (1,0) [0|1] "" Vector__XXX

BO_ 49 CAN2_RX_031: 8 Vector__XXX
 SG_ AUTHENTICATOR : 7|27@0+ (1,0) [0|134217727] "" Vector__XXX
 SG_ SECOC_FRESHNESS : 28|5@0+ (1,0) [0|31] "" Vector__XXX

BO_ 51 CAN2_RX_033: 8 Vector__XXX
 SG_ AUTHENTICATOR : 7|27@0+ (1,0) [0|134217727] "" Vector__XXX
 SG_ SECOC_FRESHNESS : 28|5@0+ (1,0) [0|31] "" Vector__XXX

BO_ 101 CAN2_RX_065: 20 Vector__XXX
 SG_ AUTHENTICATOR : 7|32@0+ (1,0) [0|4294967295] "" Vector__XXX
 SG_ SECOC_FRESHNESS : 39|5@0+ (1,0) [0|31] "" Vector__XXX
 SG_ SECOC_AUX : 34|3@0+ (1,0) [0|7] "" Vector__XXX

BO_ 588 CAN2_RX_24C: 8 Vector__XXX
 SG_ AUTHENTICATOR : 7|27@0+ (1,0) [0|134217727] "" Vector__XXX
 SG_ SECOC_FRESHNESS : 28|5@0+ (1,0) [0|31] "" Vector__XXX

BO_ 874 CAN2_RX_36A: 8 Vector__XXX
 SG_ AUTHENTICATOR : 7|27@0+ (1,0) [0|134217727] "" Vector__XXX
 SG_ SECOC_FRESHNESS : 28|5@0+ (1,0) [0|31] "" Vector__XXX

BO_ 1300 CAN2_RX_514: 12 Vector__XXX
 SG_ AUTHENTICATOR : 7|32@0+ (1,0) [0|4294967295] "" Vector__XXX
 SG_ SECOC_FRESHNESS : 39|5@0+ (1,0) [0|31] "" Vector__XXX
 SG_ SECOC_AUX : 34|3@0+ (1,0) [0|7] "" Vector__XXX

BO_ 970 CAN2_RX_3CA: 8 Vector__XXX
 SG_ SECOC_FRESHNESS_VALUE : 0|32@1+ (1,0) [0|4294967295] "" Vector__XXX

BO_ 1375 ECP_E_WHEEL_CALIBRATION_FV: 8 ECP_E
 SG_ SECOC_FRESHNESS_VALUE : 0|32@1+ (1,0) [0|4294967295] "" Vector__XXX

BO_ 1380 CAN2_RX_564: 8 Vector__XXX
 SG_ SECOC_FRESHNESS_VALUE : 0|32@1+ (1,0) [0|4294967295] "" Vector__XXX

BO_ 171 CAN2_RX_0AB: 12 CGM

BO_ 529 CAN2_RX_211: 64 Vector__XXX

BO_ 1171 CAN2_RX_493: 8 ARS

BO_ 1413 CAN2_RX_585: 1 CGM

CM_ "GM Global B Super Cruise 1 physical CAN2 database. Unknown transmitters use Vector__XXX.";
CM_ BO_ 47 "Transmitter: ECP_E. Received by ACP3_MCU; carries actual axle torque and a second axle-torque channel whose precise role is not yet identified.";
CM_ BO_ 50 "Transmitter: ECP_E. Received by ACP3_MCU; carries estimated gear and shift-lever position.";
CM_ BO_ 58 "Transmitter: EPS. Received by ACP3_MCU; authenticated EPS data. The application fields other than the rolling counter are not yet identified.";
CM_ BO_ 59 "Transmitter: EBCM. Received by ACP3_MCU; carries brake-pedal position, brake torque, wheel-distance edge counters, and wheel angular velocities.";
CM_ BO_ 62 "Transmitter: BCM. Received by ACP3_MCU; application layout is unknown.";
CM_ BO_ 63 "Transmitter: ECP_E. Received by ACP3_MCU; carries nominal road-load axle torque.";
CM_ BO_ 66 "Transmitter: EBCM. Received by ACP3_MCU; carries driver-applied brake pressure. The field identity is supported by its scaling and correlation with brake-pedal position; the physical unit is not yet established.";
CM_ BO_ 72 "Transmitter: ECP_E. Received by ACP3_MCU; carries primary electric transmission range and electronic-shift status.";
CM_ BO_ 84 "Transmitter: EPS. Received by ACP3_MCU; carries steering-wheel angle, angle gradient, calibration status, and validity state.";
CM_ BO_ 174 "Transmitter: ECP_E. Received by ACP3_MCU; application layout is unknown.";
CM_ BO_ 175 "Transmitter: ECP_E. Received by ACP3_MCU; application layout is unknown.";
CM_ BO_ 182 "Transmitter: CGM. Raw-forwarded by CGM to CAN2 from CAN4 0x209 or CAN8 0x0C0 and received by ACP3_MCU; application layout is unknown. CGM route: raw CAN4 0x209 -> CAN2; raw CAN8 0x0C0 -> CAN2; network-to-CAN relay on CAN2.";
CM_ BO_ 186 "Transmitter: CGM. Generated from ACP3_SOC network data and received by ACP3_MCU; application layout is unknown. CGM route: network-to-CAN relay on CAN2 from ACP3_SOC data.";
CM_ BO_ 192 "Transmitter: EBCM. Received by ACP3_MCU; application layout is unknown.";
CM_ BO_ 226 "Transmitter: ECP_E. Received by ACP3_MCU; application layout is unknown.";
CM_ BO_ 545 "Received by ACP3_MCU; transmitter and application layout are unknown.";
CM_ BO_ 586 "Transmitter remains unresolved. Received by ACP3_MCU; application layout is unknown.";
CM_ BO_ 597 "Transmitter: CGM. Raw-forwarded by CGM from CAN5 to CAN2 and received by ACP3_MCU; application layout is unknown. CGM route: raw CAN5 0x255 -> CAN2.";
CM_ BO_ 610 "Transmitter: ECP_E. Received by ACP3_MCU; carries average non-driven vehicle speed.";
CM_ BO_ 614 "Transmitter: ECP_E. Received by ACP3_MCU; carries average driven vehicle speed.";
CM_ BO_ 615 "Transmitter: ECP_E. Received by ACP3_MCU; application layout is unknown.";
CM_ BO_ 616 "Transmitter: VICM. Received by ACP3_MCU; application layout is unknown.";
CM_ BO_ 622 "Transmitter: CGM. Raw-forwarded by CGM from CAN5 to CAN2 and received by ACP3_MCU; application layout is unknown. CGM route: raw CAN5 0x26E -> CAN2.";
CM_ BO_ 624 "Transmitter: EBCM. Received by ACP3_MCU; carries actual vehicle acceleration and the four wheel-direction states.";
CM_ BO_ 634 "Transmitter: BCM. Received by ACP3_MCU; application layout is unknown.";
CM_ BO_ 640 "Transmitter: CGM. Raw-forwarded by CGM from CAN5 to CAN2 and received by ACP3_MCU; application layout is unknown. CGM route: raw CAN5 0x280 -> CAN2.";
CM_ BO_ 659 "Transmitter: CGM. Transmitted by CGM and received by ACP3_MCU; payload is assembled from decoded gateway signals, but its application semantics are unknown. CGM route: signal-gateway output on CAN2.";
CM_ BO_ 674 "Received by ACP3_MCU; transmitter and application layout are unknown.";
CM_ BO_ 675 "Transmitter: EPS. Full freshness value for EPS_STEERING_WHEEL_DATA.";
CM_ BO_ 683 "Received by ACP3_MCU; transmitter and application layout are unknown.";
CM_ BO_ 691 "Transmitter: EBCM. Full freshness value shared by EBCM_BRAKE_WHEEL_DATA and EBCM_DRIVER_APPLIED_BRAKE_PRESSURE.";
CM_ BO_ 693 "Received by ACP3_MCU; transmitter and application layout are unknown.";
CM_ BO_ 702 "Transmitter: CGM. Raw-forwarded by CGM from CAN9 to CAN2 and received by ACP3_MCU; application layout is unknown. CGM route: raw CAN9 0x2BE -> CAN2.";
CM_ BO_ 703 "Transmitter: EBCM. Received by ACP3_MCU; application layout is unknown.";
CM_ BO_ 725 "Transmitter: CGM. Transmitted by CGM and received by ACP3_MCU; payload is assembled from decoded gateway signals, but its application semantics are unknown. CGM route: signal-gateway output on CAN2.";
CM_ BO_ 726 "Transmitter: CGM. Transmitted by CGM and received by ACP3_MCU; payload is assembled from decoded gateway signals, but its application semantics are unknown. CGM route: signal-gateway output on CAN2.";
CM_ BO_ 727 "Transmitter: TCP. Received by ACP3_MCU; application layout is unknown.";
CM_ BO_ 728 "Transmitter: CGM. Raw-forwarded by CGM from CAN9 0x2A9 to CAN2 and received by ACP3_MCU; application layout is unknown. CGM route: raw CAN9 0x2A9 -> CAN2.";
CM_ BO_ 873 "Transmitter: EBCM. Received by ACP3_MCU; application layout is unknown.";
CM_ BO_ 876 "Transmitter: CGM. Raw-forwarded by CGM from CAN9 to CAN2 and received by ACP3_MCU; application layout is unknown. CGM route: raw CAN9 0x36C -> CAN2.";
CM_ BO_ 878 "Transmitter: BCM. Received by ACP3_MCU; application layout is unknown.";
CM_ BO_ 879 "Transmitter: ECP_E. Received by ACP3_MCU; carries propulsion-system, park/neutral, engine-running, crank, remote-start, and related status.";
CM_ BO_ 880 "Transmitter: CGM. Transmitted by CGM; the payload is assembled from decoded gateway signals. CGM route: signal-gateway output on CAN2.";
CM_ BO_ 898 "Transmitter: CGM. Raw-forwarded by CGM from CAN5 to CAN2 and received by ACP3_MCU; application layout is unknown. CGM route: raw CAN5 0x382 -> CAN2.";
CM_ BO_ 901 "Received by ACP3_MCU; transmitter and application layout are unknown.";
CM_ BO_ 904 "Received by ACP3_MCU; transmitter and application layout are unknown.";
CM_ BO_ 905 "Received by ACP3_MCU; transmitter and application layout are unknown.";
CM_ BO_ 906 "Received by ACP3_MCU; transmitter and application layout are unknown.";
CM_ BO_ 907 "Received by ACP3_MCU; transmitter and application layout are unknown.";
CM_ BO_ 909 "Received by ACP3_MCU; transmitter and application layout are unknown.";
CM_ BO_ 919 "Transmitter: EBCM. Full freshness value for EBCM_WHEEL_ROTATION_DIRECTIONAL_STATUS.";
CM_ BO_ 920 "Received by ACP3_MCU; transmitter and application layout are unknown.";
CM_ BO_ 923 "Received by ACP3_MCU; transmitter and application layout are unknown.";
CM_ BO_ 930 "Transmitter: CGM. Transmitted by CGM and received by ACP3_MCU; payload is assembled from decoded gateway signals, but its application semantics are unknown. CGM route: signal-gateway output on CAN2.";
CM_ BO_ 934 "Transmitter: ECP_E. Received by ACP3_MCU; application layout is unknown.";
CM_ BO_ 938 "Transmitter: EBCM. Received by ACP3_MCU; application layout is unknown.";
CM_ BO_ 945 "Received by ACP3_MCU; transmitter and application layout are unknown.";
CM_ BO_ 962 "Transmitter: CGM. Transmitted by CGM and received by ACP3_MCU; reports protected system-power-mode fail-safe status. CGM route: signal-gateway output on CAN2.";
CM_ BO_ 963 "Transmitter: CGM. Transmitted by CGM and received by ACP3_MCU; carries authenticated power-state inputs. CGM route: signal-gateway output on CAN2.";
CM_ BO_ 964 "Transmitter: CGM. Transmitted by CGM and received by ACP3_MCU; payload is assembled from decoded gateway signals, but its application semantics are unknown. CGM route: signal-gateway output on CAN2.";
CM_ BO_ 972 "Received by ACP3_MCU; transmitter and application layout are unknown.";
CM_ BO_ 1149 "Transmitter: CGM. Raw-forwarded by CGM from CAN5 to CAN2 and received by ACP3_MCU; application layout is unknown. CGM route: raw CAN5 0x47D -> CAN2.";
CM_ BO_ 1152 "Transmitter: CGM. Raw-forwarded by CGM from CAN5 to CAN2 and received by ACP3_MCU; application layout is unknown. CGM route: raw CAN5 0x480 -> CAN2.";
CM_ BO_ 1244 "Transmitter: CGM. Transmitted by CGM and received by ACP3_MCU; payload is assembled from decoded gateway signals, but its application semantics are unknown. CGM route: signal-gateway output on CAN2.";
CM_ BO_ 1264 "Transmitter: ECP_E. Received by ACP3_MCU; application layout is unknown.";
CM_ BO_ 1285 "Received by ACP3_MCU; transmitter and application layout are unknown.";
CM_ BO_ 1298 "Transmitter: BCM. Received by ACP3_MCU; application layout is unknown.";
CM_ BO_ 1302 "Transmitter: ECP_E. Received by ACP3_MCU; carries front and rear wheel distance per revolution.";
CM_ BO_ 1308 "Transmitter: EBCM. Received by ACP3_MCU; carries the front/rear wheel-edge counts per revolution. The two axle assignments cannot yet be distinguished because both observed values are equal.";
CM_ BO_ 1313 "Transmitter: VICM. Received by ACP3_MCU; application layout is unknown.";
CM_ BO_ 1314 "Transmitter: DSM. Received by ACP3_MCU; application layout is unknown.";
CM_ BO_ 1315 "Transmitter: CGM. Raw-forwarded by CGM from CAN5 to CAN2 and received by ACP3_MCU; application layout is unknown. CGM route: raw CAN5 0x523 -> CAN2.";
CM_ BO_ 1316 "Transmitter: BCM. Received by ACP3_MCU; application layout is unknown.";
CM_ BO_ 1319 "Transmitter: TCP. Received by ACP3_MCU; application layout is unknown.";
CM_ BO_ 1324 "Transmitter: BCM. Received by ACP3_MCU; application layout is unknown.";
CM_ BO_ 1355 "Transmitter: ACP3_MCU. Also registered as an ACP3_MCU receive PDU.";
CM_ BO_ 1359 "Received by ACP3_MCU; transmitter and application layout are unknown.";
CM_ BO_ 1369 "Transmitter: ECP_E. Full freshness value shared by ECP_E_NON_DRIVEN_VEHICLE_SPEED and ECP_E_DRIVEN_VEHICLE_SPEED.";
CM_ BO_ 1373 "Transmitter: CGM. Raw-forwarded by CGM from CAN9 to CAN2 and received by ACP3_MCU; application layout is unknown. CGM route: raw CAN9 0x55D -> CAN2.";
CM_ BO_ 1374 "Received by ACP3_MCU; transmitter and application layout are unknown.";
CM_ BO_ 1375 "Transmitter: ECP_E. Full freshness value used by ECP_E_WHEEL_DISTANCE_PER_REVOLUTION.";
CM_ BO_ 1376 "Received by ACP3_MCU; transmitter and application layout are unknown.";
CM_ BO_ 1377 "Received by ACP3_MCU; transmitter and application layout are unknown.";
CM_ BO_ 1384 "Transmitter: CGM. Raw-forwarded by CGM to CAN2 from CAN4 or CAN9 and received by ACP3_MCU; application layout is unknown. CGM route: raw CAN4 0x568 -> CAN2; raw CAN9 0x568 -> CAN2.";
CM_ BO_ 1385 "Transmitter: CGM. Raw-forwarded by CGM from CAN5 to CAN2 and received by ACP3_MCU; application layout is unknown. CGM route: raw CAN5 0x569 -> CAN2.";
CM_ BO_ 1387 "Received by ACP3_MCU; transmitter and application layout are unknown.";
CM_ BO_ 1394 "Received by ACP3_MCU; transmitter and application layout are unknown.";
CM_ BO_ 1396 "Received by ACP3_MCU; transmitter and application layout are unknown.";
CM_ BO_ 1402 "Received by ACP3_MCU; transmitter and application layout are unknown.";
CM_ BO_ 1403 "Received by ACP3_MCU; transmitter and application layout are unknown.";
CM_ BO_ 1404 "Transmitter: ECP_E. Full freshness value for ECP_E_PROPULSION_INFO.";
CM_ BO_ 1407 "Transmitter: CGM. Transmitted by CGM and received by ACP3_MCU; payload is assembled from decoded gateway signals, but its application semantics are unknown. CGM route: signal-gateway output on CAN2.";
CM_ BO_ 1408 "Transmitter: BCM. Received by ACP3_MCU; application layout is unknown.";
CM_ BO_ 1409 "Transmitter: BCM. Received by ACP3_MCU; application layout is unknown.";
CM_ BO_ 1410 "Received by ACP3_MCU; transmitter and application layout are unknown.";
CM_ BO_ 1412 "Transmitter: RRR_SIDE. Received by ACP3_MCU; application layout is unknown.";
CM_ BO_ 1424 "Transmitter: CGM. Transmitted by CGM and received by ACP3_MCU; payload is assembled from decoded gateway signals, but its application semantics are unknown. CGM route: signal-gateway output on CAN2.";
CM_ BO_ 1426 "Received by ACP3_MCU; transmitter and application layout are unknown.";
CM_ BO_ 1427 "Received by ACP3_MCU; transmitter and application layout are unknown.";
CM_ BO_ 1428 "Received by ACP3_MCU; transmitter and application layout are unknown.";
CM_ BO_ 1429 "Received by ACP3_MCU; transmitter and application layout are unknown.";
CM_ BO_ 1430 "Received by ACP3_MCU; transmitter and application layout are unknown.";
CM_ BO_ 1433 "Received by ACP3_MCU; transmitter and application layout are unknown.";
CM_ BO_ 1435 "Received by ACP3_MCU; transmitter and application layout are unknown.";
CM_ BO_ 1441 "Transmitter: CGM. Transmitted by CGM and received by ACP3_MCU; payload is assembled from decoded gateway signals, but its application semantics are unknown. CGM route: signal-gateway output on CAN2.";
CM_ BO_ 1442 "Transmitter: CGM. Raw-forwarded by CGM from CAN9 0x5A1 to CAN2 and received by ACP3_MCU; application layout is unknown. CGM route: raw CAN9 0x5A1 -> CAN2.";
CM_ BO_ 1444 "Transmitter: CGM. Raw-forwarded by CGM from CAN8 0x594 to CAN2 and received by ACP3_MCU; application layout is unknown. CGM route: raw CAN8 0x594 -> CAN2.";
CM_ BO_ 1466 "Transmitter: CGM. Transmitted by CGM and received by ACP3_MCU; payload is assembled from decoded gateway signals, but its application semantics are unknown. CGM route: signal-gateway output on CAN2.";
CM_ BO_ 1469 "Transmitter: CGM. Transmitted by CGM and received by ACP3_MCU; payload is assembled from decoded gateway signals, but its application semantics are unknown. CGM route: signal-gateway output on CAN2.";
CM_ BO_ 1476 "Transmitter: CGM. Raw-forwarded by CGM from CAN5 0x494 to CAN2 and received by ACP3_MCU; application layout is unknown. CGM route: raw CAN5 0x494 -> CAN2.";
CM_ BO_ 1481 "Transmitter: EBCM. Received by ACP3_MCU; application layout is unknown.";
CM_ BO_ 1482 "Transmitter: EBCM. Received by ACP3_MCU; application layout is unknown.";
CM_ BO_ 1483 "Transmitter: EBCM. Received by ACP3_MCU; application layout is unknown.";
CM_ BO_ 1490 "Received by ACP3_MCU; transmitter and application layout are unknown.";
CM_ BO_ 1529 "Transmitter: CGM. Transmitted by CGM and received by ACP3_MCU; payload is assembled from decoded gateway signals, but its application semantics are unknown. CGM route: signal-gateway output on CAN2.";
CM_ BO_ 171 "Transmitter: CGM. Application layout is not yet defined. CGM route: raw CAN3 0x0AB -> CAN2.";
CM_ BO_ 525 "Transmitter: ACP3_MCU. Longitudinal-control mode and axle-torque-request status. Complements request status 0x20E and axle-torque status 0x24B. Transmitted every 50 ms.";
CM_ SG_ 525 LongitudinalControlMode "Longitudinal controller operating state. States 4 and 5 permit axle-torque output.";
CM_ SG_ 525 RollingCounter "Modulo-four application rolling counter.";
CM_ SG_ 525 AxleTorqueRequestMode "Axle-torque request mode, including request direction/type.";
CM_ SG_ 525 AxleTorqueRequestPathActive "Axle-torque request path active.";
CM_ BO_ 526 "Transmitter: ACP3_MCU. Longitudinal request and authorization status.";
CM_ SG_ 526 AxleTorqueRequestActive "Same logical state as AdaptiveCruiseBrakeControlActive.";
CM_ SG_ 526 AdaptiveCruiseBrakeControlActive "Same logical state as AxleTorqueRequestActive.";
CM_ BO_ 587 "Transmitter: ACP3_MCU. Axle-torque values, status, and validity.";
CM_ SG_ 587 AxleTorqueFieldA "First axle-torque value. Valid when AxleTorqueValid is set.";
CM_ SG_ 587 AxleTorqueFieldB "Second axle-torque value. Valid when AxleTorqueValid is set.";
CM_ SG_ 587 AxleTorqueStatusA "Status for AxleTorqueFieldA.";
CM_ SG_ 587 AxleTorqueStatusB "Status for AxleTorqueFieldB.";
CM_ SG_ 587 AxleTorqueValid "Validity of both axle-torque values.";
CM_ BO_ 925 "Transmitter: ACP3_MCU. Full freshness value for ACP3_MCU_LONGITUDINAL_CONTROL_STATUS.";
CM_ BO_ 529 "Transmitter remains unresolved. Application layout is not yet defined.";
CM_ BO_ 635 "Transmitter: EBCM. Application layout is not yet defined.";
CM_ BO_ 1171 "Transmitter: ARS. Application layout is not yet defined.";
CM_ BO_ 1413 "Transmitter: CGM. Application layout is not yet defined. CGM route: signal-gateway output on CAN2.";
CM_ BO_ 225 "Transmitter: ACP3_MCU. Additional CGM route: network-to-CAN relay on CAN2.";
CM_ BO_ 1321 "Transmitter: ACP3_MCU. Additional CGM route: network-to-CAN relay on CAN2.";
CM_ BO_ 1405 "Transmitter: CGM. CGM route: signal-gateway output on CAN2.";
CM_ BO_ 1500 "Transmitter: ACP3_MCU. Additional CGM route: network-to-CAN relay on CAN2 from ACP3_SOC data.";
CM_ BO_ 1829 "Transmitter: ACP3_MCU. Additional CGM route: network-to-CAN relay on CAN2.";
CM_ SG_ 47 SecondaryAxleTorque "The payload and scale are established, but this channel's precise axle-torque role remains unresolved.";
CM_ SG_ 66 DriverAppliedBrakePressure "The physical unit has not yet been established.";
CM_ SG_ 1308 WheelEdgesPerRevolutionFieldA "One of the front/rear wheel-edge calibration values; its axle assignment is not yet established.";
CM_ SG_ 1308 WheelEdgesPerRevolutionFieldB "One of the front/rear wheel-edge calibration values; its axle assignment is not yet established.";
CM_ SG_ 963 PrimaryRunCrankCommand "The exact command-value labels remain unknown.";

BA_DEF_ BO_ "GenMsgCycleTime" INT 0 65535;
BA_DEF_ BO_ "VFrameFormat" ENUM "StandardCAN","ExtendedCAN","reserved","J1939PG","StandardCAN_FD","ExtendedCAN_FD";
BA_DEF_ BO_ "SecOCKeyRole" STRING;
BA_DEF_ BO_ "SecOCObservedKeyFamily" STRING;
BA_DEF_ BO_ "SecOCKeyCandidates" STRING;
BA_DEF_ BO_ "SecOCDataId" INT 0 255;
BA_DEF_ BO_ "SecOCCompanionId" INT 0 536870911;

BA_DEF_DEF_ "GenMsgCycleTime" 0;
BA_DEF_DEF_ "VFrameFormat" "StandardCAN";

BA_ "SecOCObservedKeyFamily" BO_ 47 "shared_secoc_family_b";
BA_ "SecOCKeyCandidates" BO_ 47 "secoc_key_032_group,secoc_key_048_group,secoc_key_266_group,secoc_key_36f_group";
BA_ "SecOCKeyRole" BO_ 50 "secoc_key_032_group";
BA_ "SecOCObservedKeyFamily" BO_ 50 "shared_secoc_family_b";
BA_ "SecOCKeyRole" BO_ 58 "safety_control_key";
BA_ "SecOCKeyRole" BO_ 59 "shared_secoc_key_a";
BA_ "SecOCKeyRole" BO_ 66 "shared_secoc_key_a";
BA_ "SecOCKeyRole" BO_ 72 "secoc_key_048_group";
BA_ "SecOCObservedKeyFamily" BO_ 72 "shared_secoc_family_b";
BA_ "SecOCKeyRole" BO_ 84 "safety_control_key";
BA_ "SecOCDataId" BO_ 84 1;
BA_ "SecOCCompanionId" BO_ 84 675;
BA_ "SecOCKeyRole" BO_ 87 "safety_control_key";
BA_ "SecOCDataId" BO_ 87 1;
BA_ "SecOCCompanionId" BO_ 87 914;
BA_ "SecOCKeyRole" BO_ 187 "safety_control_key";
BA_ "SecOCDataId" BO_ 187 1;
BA_ "SecOCCompanionId" BO_ 187 927;
BA_ "SecOCObservedKeyFamily" BO_ 226 "shared_secoc_family_b";
BA_ "SecOCKeyCandidates" BO_ 226 "secoc_key_032_group,secoc_key_048_group,secoc_key_266_group,secoc_key_36f_group";
BA_ "SecOCKeyRole" BO_ 525 "safety_control_key";
BA_ "SecOCDataId" BO_ 525 1;
BA_ "SecOCCompanionId" BO_ 525 925;
BA_ "SecOCKeyRole" BO_ 526 "safety_control_key";
BA_ "SecOCDataId" BO_ 526 1;
BA_ "SecOCCompanionId" BO_ 526 902;
BA_ "SecOCKeyRole" BO_ 587 "safety_control_key";
BA_ "SecOCDataId" BO_ 587 1;
BA_ "SecOCCompanionId" BO_ 587 971;
BA_ "SecOCObservedKeyFamily" BO_ 610 "shared_secoc_family_b";
BA_ "SecOCKeyCandidates" BO_ 610 "secoc_key_032_group,secoc_key_048_group,secoc_key_266_group,secoc_key_36f_group";
BA_ "SecOCKeyRole" BO_ 614 "secoc_key_266_group";
BA_ "SecOCObservedKeyFamily" BO_ 614 "shared_secoc_family_b";
BA_ "SecOCObservedKeyFamily" BO_ 615 "shared_secoc_family_b";
BA_ "SecOCKeyCandidates" BO_ 615 "secoc_key_032_group,secoc_key_048_group,secoc_key_266_group,secoc_key_36f_group";
BA_ "SecOCKeyRole" BO_ 624 "shared_secoc_key_a";
BA_ "SecOCKeyRole" BO_ 625 "safety_control_key";
BA_ "SecOCDataId" BO_ 625 1;
BA_ "SecOCCompanionId" BO_ 625 924;
BA_ "SecOCKeyRole" BO_ 635 "shared_secoc_key_a";
BA_ "SecOCKeyRole" BO_ 644 "safety_control_key";
BA_ "SecOCDataId" BO_ 644 1;
BA_ "SecOCCompanionId" BO_ 644 974;
BA_ "SecOCKeyRole" BO_ 873 "shared_secoc_key_a";
BA_ "SecOCKeyRole" BO_ 879 "secoc_key_36f_group";
BA_ "SecOCObservedKeyFamily" BO_ 879 "shared_secoc_family_b";
BA_ "SecOCKeyRole" BO_ 880 "central_gateway_key";
BA_ "SecOCDataId" BO_ 880 1;
BA_ "SecOCCompanionId" BO_ 880 1405;
BA_ "SecOCKeyRole" BO_ 1117 "safety_control_key";
BA_ "SecOCDataId" BO_ 1117 1;
BA_ "SecOCCompanionId" BO_ 1117 1949;
BA_ "SecOCObservedKeyFamily" BO_ 1302 "shared_secoc_family_b";
BA_ "SecOCKeyCandidates" BO_ 1302 "secoc_key_032_group,secoc_key_048_group,secoc_key_266_group,secoc_key_36f_group";
BA_ "SecOCKeyRole" BO_ 1308 "shared_secoc_key_a";
BA_ "SecOCKeyRole" BO_ 1323 "safety_control_key";
BA_ "SecOCDataId" BO_ 1323 1;
BA_ "SecOCCompanionId" BO_ 1323 1383;
BA_ "SecOCKeyRole" BO_ 1325 "safety_control_key";
BA_ "SecOCDataId" BO_ 1325 1;
BA_ "SecOCCompanionId" BO_ 1325 1393;
BA_ "GenMsgCycleTime" BO_ 87 10;
BA_ "GenMsgCycleTime" BO_ 187 10;
BA_ "GenMsgCycleTime" BO_ 675 160;
BA_ "GenMsgCycleTime" BO_ 225 50;
BA_ "GenMsgCycleTime" BO_ 525 50;
BA_ "GenMsgCycleTime" BO_ 526 50;
BA_ "GenMsgCycleTime" BO_ 587 10;
BA_ "GenMsgCycleTime" BO_ 625 10;
BA_ "GenMsgCycleTime" BO_ 644 10;
BA_ "GenMsgCycleTime" BO_ 701 100;
BA_ "GenMsgCycleTime" BO_ 880 250;
BA_ "GenMsgCycleTime" BO_ 902 800;
BA_ "GenMsgCycleTime" BO_ 914 160;
BA_ "GenMsgCycleTime" BO_ 924 160;
BA_ "GenMsgCycleTime" BO_ 925 800;
BA_ "GenMsgCycleTime" BO_ 927 160;
BA_ "GenMsgCycleTime" BO_ 941 250;
BA_ "GenMsgCycleTime" BO_ 947 250;
BA_ "GenMsgCycleTime" BO_ 949 500;
BA_ "GenMsgCycleTime" BO_ 950 500;
BA_ "GenMsgCycleTime" BO_ 951 500;
BA_ "GenMsgCycleTime" BO_ 952 500;
BA_ "GenMsgCycleTime" BO_ 962 1000;
BA_ "GenMsgCycleTime" BO_ 963 1000;
BA_ "GenMsgCycleTime" BO_ 971 160;
BA_ "GenMsgCycleTime" BO_ 974 160;
BA_ "GenMsgCycleTime" BO_ 1026 1000;
BA_ "GenMsgCycleTime" BO_ 1027 1000;
BA_ "GenMsgCycleTime" BO_ 1117 1000;
BA_ "GenMsgCycleTime" BO_ 1237 1000;
BA_ "GenMsgCycleTime" BO_ 1239 1000;
BA_ "GenMsgCycleTime" BO_ 1254 1000;
BA_ "GenMsgCycleTime" BO_ 1304 1000;
BA_ "GenMsgCycleTime" BO_ 1318 1000;
BA_ "GenMsgCycleTime" BO_ 1321 1000;
BA_ "GenMsgCycleTime" BO_ 1323 1000;
BA_ "GenMsgCycleTime" BO_ 1325 1000;
BA_ "GenMsgCycleTime" BO_ 1349 1000;
BA_ "GenMsgCycleTime" BO_ 1354 1000;
BA_ "GenMsgCycleTime" BO_ 1355 1000;
BA_ "GenMsgCycleTime" BO_ 1383 3500;
BA_ "GenMsgCycleTime" BO_ 1393 3500;
BA_ "GenMsgCycleTime" BO_ 1405 1000;
BA_ "GenMsgCycleTime" BO_ 1406 1000;
BA_ "GenMsgCycleTime" BO_ 1415 1000;
BA_ "GenMsgCycleTime" BO_ 1416 1000;
BA_ "GenMsgCycleTime" BO_ 1417 1000;
BA_ "GenMsgCycleTime" BO_ 1421 1000;
BA_ "GenMsgCycleTime" BO_ 1422 1000;
BA_ "GenMsgCycleTime" BO_ 1431 1000;
BA_ "GenMsgCycleTime" BO_ 1449 1000;
BA_ "GenMsgCycleTime" BO_ 1498 1000;
BA_ "GenMsgCycleTime" BO_ 1499 1000;
BA_ "GenMsgCycleTime" BO_ 1500 1000;
BA_ "GenMsgCycleTime" BO_ 1535 1000;
BA_ "GenMsgCycleTime" BO_ 1811 1000;
BA_ "GenMsgCycleTime" BO_ 1818 1000;
BA_ "GenMsgCycleTime" BO_ 1822 1000;
BA_ "GenMsgCycleTime" BO_ 1828 1000;
BA_ "GenMsgCycleTime" BO_ 1829 1000;
BA_ "GenMsgCycleTime" BO_ 1949 3500;
BA_ "GenMsgCycleTime" BO_ 2147745830 1000;
BA_ "VFrameFormat" BO_ 47 4;
BA_ "VFrameFormat" BO_ 50 4;
BA_ "VFrameFormat" BO_ 58 4;
BA_ "VFrameFormat" BO_ 59 4;
BA_ "VFrameFormat" BO_ 62 4;
BA_ "VFrameFormat" BO_ 63 4;
BA_ "VFrameFormat" BO_ 66 4;
BA_ "VFrameFormat" BO_ 72 4;
BA_ "VFrameFormat" BO_ 84 4;
BA_ "VFrameFormat" BO_ 87 4;
BA_ "VFrameFormat" BO_ 174 4;
BA_ "VFrameFormat" BO_ 175 4;
BA_ "VFrameFormat" BO_ 182 4;
BA_ "VFrameFormat" BO_ 186 4;
BA_ "VFrameFormat" BO_ 187 4;
BA_ "VFrameFormat" BO_ 192 4;
BA_ "VFrameFormat" BO_ 225 4;
BA_ "VFrameFormat" BO_ 226 4;
BA_ "VFrameFormat" BO_ 525 4;
BA_ "VFrameFormat" BO_ 526 4;
BA_ "VFrameFormat" BO_ 545 4;
BA_ "VFrameFormat" BO_ 586 4;
BA_ "VFrameFormat" BO_ 587 4;
BA_ "VFrameFormat" BO_ 597 4;
BA_ "VFrameFormat" BO_ 610 4;
BA_ "VFrameFormat" BO_ 614 4;
BA_ "VFrameFormat" BO_ 615 4;
BA_ "VFrameFormat" BO_ 616 4;
BA_ "VFrameFormat" BO_ 622 4;
BA_ "VFrameFormat" BO_ 624 4;
BA_ "VFrameFormat" BO_ 625 4;
BA_ "VFrameFormat" BO_ 634 4;
BA_ "VFrameFormat" BO_ 635 4;
BA_ "VFrameFormat" BO_ 640 4;
BA_ "VFrameFormat" BO_ 644 4;
BA_ "VFrameFormat" BO_ 659 4;
BA_ "VFrameFormat" BO_ 674 4;
BA_ "VFrameFormat" BO_ 675 4;
BA_ "VFrameFormat" BO_ 683 4;
BA_ "VFrameFormat" BO_ 691 4;
BA_ "VFrameFormat" BO_ 693 4;
BA_ "VFrameFormat" BO_ 694 4;
BA_ "VFrameFormat" BO_ 701 4;
BA_ "VFrameFormat" BO_ 702 4;
BA_ "VFrameFormat" BO_ 703 4;
BA_ "VFrameFormat" BO_ 725 4;
BA_ "VFrameFormat" BO_ 726 4;
BA_ "VFrameFormat" BO_ 727 4;
BA_ "VFrameFormat" BO_ 728 4;
BA_ "VFrameFormat" BO_ 873 4;
BA_ "VFrameFormat" BO_ 876 4;
BA_ "VFrameFormat" BO_ 878 4;
BA_ "VFrameFormat" BO_ 879 4;
BA_ "VFrameFormat" BO_ 898 4;
BA_ "VFrameFormat" BO_ 901 4;
BA_ "VFrameFormat" BO_ 902 4;
BA_ "VFrameFormat" BO_ 904 4;
BA_ "VFrameFormat" BO_ 905 4;
BA_ "VFrameFormat" BO_ 906 4;
BA_ "VFrameFormat" BO_ 907 4;
BA_ "VFrameFormat" BO_ 909 4;
BA_ "VFrameFormat" BO_ 914 4;
BA_ "VFrameFormat" BO_ 919 4;
BA_ "VFrameFormat" BO_ 920 4;
BA_ "VFrameFormat" BO_ 923 4;
BA_ "VFrameFormat" BO_ 924 4;
BA_ "VFrameFormat" BO_ 925 4;
BA_ "VFrameFormat" BO_ 927 4;
BA_ "VFrameFormat" BO_ 930 4;
BA_ "VFrameFormat" BO_ 934 4;
BA_ "VFrameFormat" BO_ 938 4;
BA_ "VFrameFormat" BO_ 941 4;
BA_ "VFrameFormat" BO_ 945 4;
BA_ "VFrameFormat" BO_ 947 4;
BA_ "VFrameFormat" BO_ 949 4;
BA_ "VFrameFormat" BO_ 950 4;
BA_ "VFrameFormat" BO_ 951 4;
BA_ "VFrameFormat" BO_ 952 4;
BA_ "VFrameFormat" BO_ 962 4;
BA_ "VFrameFormat" BO_ 963 4;
BA_ "VFrameFormat" BO_ 964 4;
BA_ "VFrameFormat" BO_ 971 4;
BA_ "VFrameFormat" BO_ 972 4;
BA_ "VFrameFormat" BO_ 974 4;
BA_ "VFrameFormat" BO_ 1026 4;
BA_ "VFrameFormat" BO_ 1027 4;
BA_ "VFrameFormat" BO_ 1117 4;
BA_ "VFrameFormat" BO_ 1149 4;
BA_ "VFrameFormat" BO_ 1152 4;
BA_ "VFrameFormat" BO_ 1237 4;
BA_ "VFrameFormat" BO_ 1239 4;
BA_ "VFrameFormat" BO_ 1244 4;
BA_ "VFrameFormat" BO_ 1254 4;
BA_ "VFrameFormat" BO_ 1264 4;
BA_ "VFrameFormat" BO_ 1285 4;
BA_ "VFrameFormat" BO_ 1298 4;
BA_ "VFrameFormat" BO_ 1302 4;
BA_ "VFrameFormat" BO_ 1304 4;
BA_ "VFrameFormat" BO_ 1308 4;
BA_ "VFrameFormat" BO_ 1313 4;
BA_ "VFrameFormat" BO_ 1314 4;
BA_ "VFrameFormat" BO_ 1315 4;
BA_ "VFrameFormat" BO_ 1316 4;
BA_ "VFrameFormat" BO_ 1318 4;
BA_ "VFrameFormat" BO_ 1319 4;
BA_ "VFrameFormat" BO_ 1321 4;
BA_ "VFrameFormat" BO_ 1323 4;
BA_ "VFrameFormat" BO_ 1324 4;
BA_ "VFrameFormat" BO_ 1325 4;
BA_ "VFrameFormat" BO_ 1349 4;
BA_ "VFrameFormat" BO_ 1354 4;
BA_ "VFrameFormat" BO_ 1355 4;
BA_ "VFrameFormat" BO_ 1359 4;
BA_ "VFrameFormat" BO_ 1369 4;
BA_ "VFrameFormat" BO_ 1373 4;
BA_ "VFrameFormat" BO_ 1374 4;
BA_ "VFrameFormat" BO_ 1376 4;
BA_ "VFrameFormat" BO_ 1377 4;
BA_ "VFrameFormat" BO_ 1383 4;
BA_ "VFrameFormat" BO_ 1384 4;
BA_ "VFrameFormat" BO_ 1385 4;
BA_ "VFrameFormat" BO_ 1387 4;
BA_ "VFrameFormat" BO_ 1393 4;
BA_ "VFrameFormat" BO_ 1394 4;
BA_ "VFrameFormat" BO_ 1396 4;
BA_ "VFrameFormat" BO_ 1402 4;
BA_ "VFrameFormat" BO_ 1403 4;
BA_ "VFrameFormat" BO_ 1404 4;
BA_ "VFrameFormat" BO_ 1406 4;
BA_ "VFrameFormat" BO_ 1407 4;
BA_ "VFrameFormat" BO_ 1408 4;
BA_ "VFrameFormat" BO_ 1409 4;
BA_ "VFrameFormat" BO_ 1410 4;
BA_ "VFrameFormat" BO_ 1412 4;
BA_ "VFrameFormat" BO_ 1415 4;
BA_ "VFrameFormat" BO_ 1416 4;
BA_ "VFrameFormat" BO_ 1417 4;
BA_ "VFrameFormat" BO_ 1421 4;
BA_ "VFrameFormat" BO_ 1422 4;
BA_ "VFrameFormat" BO_ 1424 4;
BA_ "VFrameFormat" BO_ 1426 4;
BA_ "VFrameFormat" BO_ 1427 4;
BA_ "VFrameFormat" BO_ 1428 4;
BA_ "VFrameFormat" BO_ 1429 4;
BA_ "VFrameFormat" BO_ 1430 4;
BA_ "VFrameFormat" BO_ 1431 4;
BA_ "VFrameFormat" BO_ 1433 4;
BA_ "VFrameFormat" BO_ 1435 4;
BA_ "VFrameFormat" BO_ 1441 4;
BA_ "VFrameFormat" BO_ 1442 4;
BA_ "VFrameFormat" BO_ 1444 4;
BA_ "VFrameFormat" BO_ 1449 4;
BA_ "VFrameFormat" BO_ 1466 4;
BA_ "VFrameFormat" BO_ 1469 4;
BA_ "VFrameFormat" BO_ 1476 4;
BA_ "VFrameFormat" BO_ 1481 4;
BA_ "VFrameFormat" BO_ 1482 4;
BA_ "VFrameFormat" BO_ 1483 4;
BA_ "VFrameFormat" BO_ 1490 4;
BA_ "VFrameFormat" BO_ 1498 4;
BA_ "VFrameFormat" BO_ 1499 4;
BA_ "VFrameFormat" BO_ 1500 4;
BA_ "VFrameFormat" BO_ 1529 4;
BA_ "VFrameFormat" BO_ 1535 4;
BA_ "VFrameFormat" BO_ 1811 4;
BA_ "VFrameFormat" BO_ 1818 4;
BA_ "VFrameFormat" BO_ 1822 4;
BA_ "VFrameFormat" BO_ 1828 4;
BA_ "VFrameFormat" BO_ 1829 4;
BA_ "VFrameFormat" BO_ 1949 4;
BA_ "VFrameFormat" BO_ 2147745830 1;
BA_ "VFrameFormat" BO_ 49 4;
BA_ "VFrameFormat" BO_ 51 4;
BA_ "VFrameFormat" BO_ 101 4;
BA_ "VFrameFormat" BO_ 588 4;
BA_ "VFrameFormat" BO_ 874 4;
BA_ "VFrameFormat" BO_ 970 4;
BA_ "VFrameFormat" BO_ 1300 4;
BA_ "VFrameFormat" BO_ 1375 4;
BA_ "VFrameFormat" BO_ 1380 4;
BA_ "SecOCDataId" BO_ 47 1;
BA_ "SecOCCompanionId" BO_ 47 674;
BA_ "SecOCDataId" BO_ 49 1;
BA_ "SecOCCompanionId" BO_ 49 674;
BA_ "SecOCDataId" BO_ 50 1;
BA_ "SecOCCompanionId" BO_ 50 674;
BA_ "SecOCDataId" BO_ 51 1;
BA_ "SecOCCompanionId" BO_ 51 674;
BA_ "SecOCDataId" BO_ 59 1;
BA_ "SecOCCompanionId" BO_ 59 691;
BA_ "SecOCDataId" BO_ 66 1;
BA_ "SecOCCompanionId" BO_ 66 691;
BA_ "SecOCDataId" BO_ 72 1;
BA_ "SecOCCompanionId" BO_ 72 674;
BA_ "SecOCDataId" BO_ 101 1;
BA_ "SecOCCompanionId" BO_ 101 674;
BA_ "SecOCDataId" BO_ 226 1;
BA_ "SecOCCompanionId" BO_ 226 906;
BA_ "SecOCDataId" BO_ 588 1;
BA_ "SecOCCompanionId" BO_ 588 970;
BA_ "SecOCDataId" BO_ 610 1;
BA_ "SecOCCompanionId" BO_ 610 1369;
BA_ "SecOCDataId" BO_ 614 1;
BA_ "SecOCCompanionId" BO_ 614 1369;
BA_ "SecOCDataId" BO_ 615 1;
BA_ "SecOCCompanionId" BO_ 615 905;
BA_ "SecOCDataId" BO_ 624 1;
BA_ "SecOCCompanionId" BO_ 624 919;
BA_ "SecOCDataId" BO_ 873 1;
BA_ "SecOCCompanionId" BO_ 873 1377;
BA_ "SecOCDataId" BO_ 874 1;
BA_ "SecOCCompanionId" BO_ 874 1380;
BA_ "SecOCDataId" BO_ 879 1;
BA_ "SecOCCompanionId" BO_ 879 1404;
BA_ "SecOCDataId" BO_ 1300 1;
BA_ "SecOCCompanionId" BO_ 1300 1375;
BA_ "SecOCDataId" BO_ 1302 1;
BA_ "SecOCCompanionId" BO_ 1302 1375;
BA_ "SecOCDataId" BO_ 1308 1;
BA_ "SecOCCompanionId" BO_ 1308 1376;
BA_ "SecOCObservedKeyFamily" BO_ 49 "shared_secoc_family_b";
BA_ "SecOCKeyCandidates" BO_ 49 "secoc_key_032_group,secoc_key_048_group,secoc_key_266_group,secoc_key_36f_group";
BA_ "SecOCObservedKeyFamily" BO_ 51 "shared_secoc_family_b";
BA_ "SecOCKeyCandidates" BO_ 51 "secoc_key_032_group,secoc_key_048_group,secoc_key_266_group,secoc_key_36f_group";
BA_ "SecOCObservedKeyFamily" BO_ 101 "shared_secoc_family_b";
BA_ "SecOCKeyCandidates" BO_ 101 "secoc_key_032_group,secoc_key_048_group,secoc_key_266_group,secoc_key_36f_group";
BA_ "SecOCObservedKeyFamily" BO_ 588 "shared_secoc_family_b";
BA_ "SecOCKeyCandidates" BO_ 588 "secoc_key_032_group,secoc_key_048_group,secoc_key_266_group,secoc_key_36f_group";
BA_ "SecOCKeyRole" BO_ 874 "shared_secoc_key_a";
BA_ "SecOCObservedKeyFamily" BO_ 1300 "shared_secoc_family_b";
BA_ "SecOCKeyCandidates" BO_ 1300 "secoc_key_032_group,secoc_key_048_group,secoc_key_266_group,secoc_key_36f_group";
BA_ "GenMsgCycleTime" BO_ 674 200;
BA_ "GenMsgCycleTime" BO_ 691 160;
BA_ "GenMsgCycleTime" BO_ 905 1064;
BA_ "GenMsgCycleTime" BO_ 906 400;
BA_ "GenMsgCycleTime" BO_ 919 1600;
BA_ "GenMsgCycleTime" BO_ 970 1600;
BA_ "GenMsgCycleTime" BO_ 1369 1600;
BA_ "GenMsgCycleTime" BO_ 1375 3500;
BA_ "GenMsgCycleTime" BO_ 1376 3500;
BA_ "GenMsgCycleTime" BO_ 1377 1000;
BA_ "GenMsgCycleTime" BO_ 1380 1000;
BA_ "GenMsgCycleTime" BO_ 1404 1000;
BA_ "SecOCDataId" BO_ 635 1;
BA_ "SecOCCompanionId" BO_ 635 694;
BA_ "GenMsgCycleTime" BO_ 694 1600;
BA_ "VFrameFormat" BO_ 171 4;
BA_ "VFrameFormat" BO_ 529 4;
BA_ "VFrameFormat" BO_ 1171 4;
BA_ "VFrameFormat" BO_ 1413 4;

VAL_ 187 SteeringWheelAngleValid 0 "Invalid" 1 "Valid";
VAL_ 47 ActualAxleTorqueInvalid 0 "Valid" 1 "Invalid";
VAL_ 47 SecondaryAxleTorqueInvalid 0 "Valid" 1 "Invalid";
VAL_ 50 ShiftLeverPositionInvalid 0 "Valid" 1 "Invalid";
VAL_ 59 BrakePedalPositionInvalid 0 "Valid" 1 "Invalid";
VAL_ 59 ChassisBrakeAxleTorqueInvalid 0 "Valid" 1 "Invalid";
VAL_ 59 LeftFrontWheelDistanceInvalid 0 "Valid" 1 "Invalid";
VAL_ 59 RightFrontWheelDistanceInvalid 0 "Valid" 1 "Invalid";
VAL_ 59 LeftRearWheelDistanceInvalid 0 "Valid" 1 "Invalid";
VAL_ 59 RightRearWheelDistanceInvalid 0 "Valid" 1 "Invalid";
VAL_ 59 LeftFrontWheelAngularVelocityInvalid 0 "Valid" 1 "Invalid";
VAL_ 59 RightFrontWheelAngularVelocityInvalid 0 "Valid" 1 "Invalid";
VAL_ 59 LeftRearWheelAngularVelocityInvalid 0 "Valid" 1 "Invalid";
VAL_ 59 RightRearWheelAngularVelocityInvalid 0 "Valid" 1 "Invalid";
VAL_ 66 DriverAppliedBrakePressureInvalid 0 "Valid" 1 "Invalid";
VAL_ 72 SecondaryEngineCompartmentAjarInvalid 0 "Valid" 1 "Invalid";
VAL_ 84 SteeringWheelAngleDataUnavailable 0 "Available" 1 "Unavailable";
VAL_ 84 SteeringWheelAngleInvalid 0 "Valid" 1 "Invalid";
VAL_ 610 AverageNonDrivenVehicleSpeedInvalid 0 "Valid" 1 "Invalid";
VAL_ 614 AverageDrivenVehicleSpeedInvalid 0 "Valid" 1 "Invalid";
VAL_ 624 ActualVehicleAccelerationInvalid 0 "Valid" 1 "Invalid";
VAL_ 879 ClutchBottomTravelAchieved 0 "Not_Achieved" 1 "Achieved";
VAL_ 879 ClutchBottomTravelAchievedInvalid 0 "Valid" 1 "Invalid";
VAL_ 879 EngineRunning 0 "Not_Running" 1 "Running";
VAL_ 879 ParkNeutralSwitchStatusInvalid 0 "Valid" 1 "Invalid";
VAL_ 879 PropulsionSystemActive 0 "Inactive" 1 "Active";
VAL_ 879 PropulsionSystemStillActive 0 "Inactive" 1 "Active";
VAL_ 879 PowertrainCrankAborted 0 "Not_Aborted" 1 "Aborted";
VAL_ 879 RemoteStartEngineRunning 0 "Not_Running" 1 "Running";
VAL_ 879 PropulsionBrakeThrottleOverrideRequired 0 "Not_Required" 1 "Required";
VAL_ 525 AxleTorqueRequestPathActive 0 "Inactive" 1 "Active";
VAL_ 526 AxleTorqueRequestActive 0 "Inactive" 1 "Active";
VAL_ 526 AdaptiveCruiseBrakeControlActive 0 "Inactive" 1 "Active";
VAL_ 526 AdaptiveCruiseBrakeRequestActive 0 "Inactive" 1 "Active";
VAL_ 526 CollisionMitigationBrakeTorqueRequestActive 0 "Inactive" 1 "Active";
VAL_ 526 LaneCenteringAcceleratorLimitRequest 0 "Inactive" 1 "Active";
VAL_ 587 AxleTorqueStatusA 0 "Unknown_Status_0" 1 "Unknown_Status_1" 2 "Unknown_Status_2" 3 "Unknown_Status_3";
VAL_ 587 AxleTorqueStatusB 0 "Unknown_Status_0" 1 "Unknown_Status_1" 2 "Unknown_Status_2" 3 "Unknown_Status_3";
VAL_ 587 AxleTorqueValid 0 "Invalid" 1 "Valid";
VAL_ 625 SteeringRequestState 0 "Unknown_State_0" 3 "Unknown_State_3" 6 "Unknown_State_6";
VAL_ 625 SteeringRequestStatus 1 "Unknown_Status_1" 2 "Unknown_Status_2";
VAL_ 625 SteeringRequestCalibrationStateFlag 0 "Inactive" 1 "Active";
VAL_ 625 SteeringRequestTransitionFlag 0 "No_Transition" 1 "Transition";
VAL_ 644 SteeringRequestState 0 "Unknown_State_0" 3 "Unknown_State_3" 6 "Unknown_State_6";
VAL_ 644 SteeringRequestStatus 1 "Unknown_Status_1" 2 "Unknown_Status_2";
VAL_ 644 SteeringRequestCalibrationStateFlag 0 "Inactive" 1 "Active";
VAL_ 644 SteeringRequestTransitionFlag 0 "No_Transition" 1 "Transition";
VAL_ 880 VehiclePowerMode 0 "Off" 1 "Accessory" 2 "Run" 3 "Start_Crank" 4 "Propulsion";
VAL_ 880 PowerModeGate 0 "Inactive" 1 "Active";
VAL_ 962 SystemPowerModeProtectionFailSafe 0 "Inactive" 1 "Active";
VAL_ 963 SystemPowerModeActive 0 "Inactive" 1 "Active";
VAL_ 2147745830 NodeStatusBit0 0 "Unknown_0" 1 "Unknown_1";
